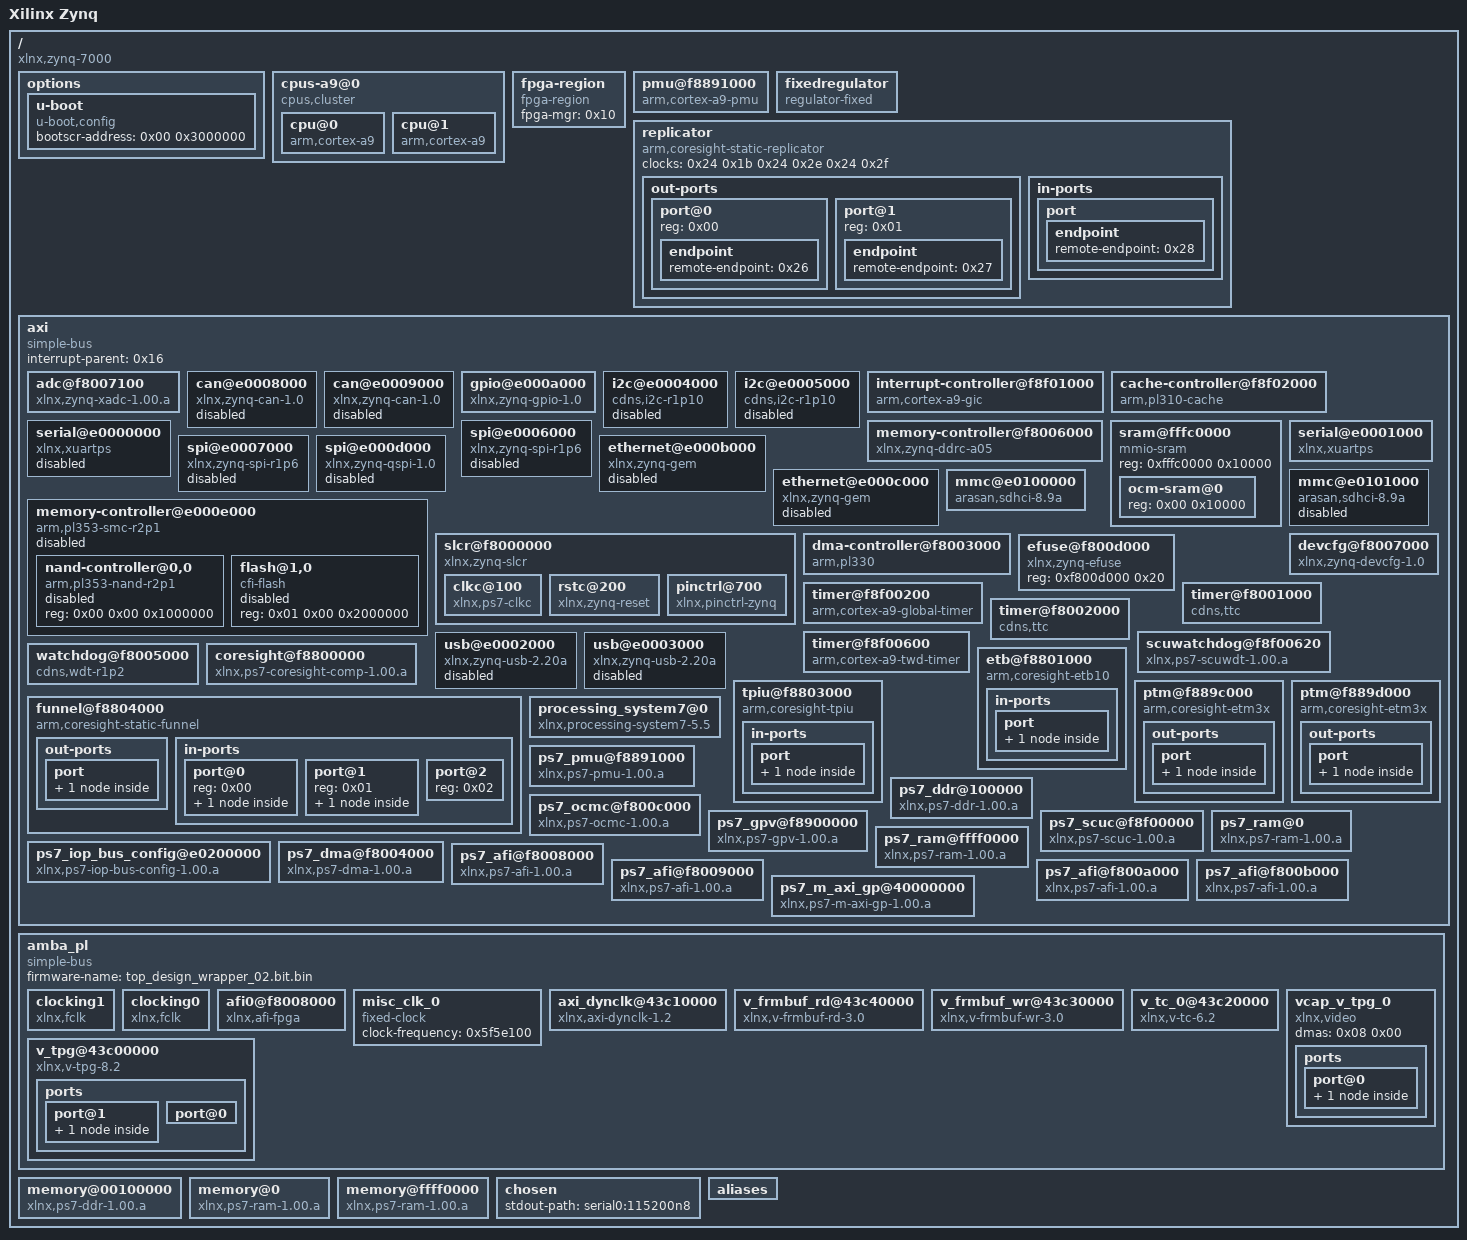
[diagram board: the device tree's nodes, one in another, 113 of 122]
/dts-v1/;

/ {
	#address-cells = <0x01>;
	#size-cells = <0x01>;
	compatible = "xlnx,zynq-7000";
	model = "Xilinx Zynq";
	device_id = "7z020";
	slrcount = <0x01>;
	family = "Zynq";
	speed_grade = "2";

	options {

		u-boot {
			compatible = "u-boot,config";
			bootscr-address = <0x00 0x3000000>;
		};
	};

	cpus-a9@0 {
		#address-cells = <0x01>;
		#size-cells = <0x00>;
		compatible = "cpus,cluster";
		address-map = <0xf0000000 0x01 0xf0000000 0x10000000 0x100000 0x02 0x100000 0x1ff00000 0x00 0x03 0x00 0x30000 0xffff0000 0x04 0xffff0000 0xfe00 0x43c00000 0x05 0x43c00000 0x10000 0x43c10000 0x06 0x43c10000 0x10000 0x43c20000 0x07 0x43c20000 0x10000 0x43c30000 0x08 0x43c30000 0x10000 0x43c40000 0x09 0x43c40000 0x10000 0xf8008000 0x0a 0xf8008000 0x1000 0xf8009000 0x0b 0xf8009000 0x1000 0xf800a000 0x0c 0xf800a000 0x1000 0xf800b000 0x0d 0xf800b000 0x1000 0xf8800000 0x0e 0xf8800000 0x100000 0xf8006000 0x0f 0xf8006000 0x1000 0xf8007000 0x10 0xf8007000 0x100 0xf8004000 0x11 0xf8004000 0x1000 0xf8003000 0x12 0xf8003000 0x1000 0xf8f00200 0x13 0xf8f00200 0x100 0xe000a000 0x14 0xe000a000 0x1000 0xf8900000 0x15 0xf8900000 0x100000 0xf8f01000 0x16 0xf8f01000 0x1000 0xe0200000 0x17 0xe0200000 0x1000 0xf8f02000 0x18 0xf8f02000 0x1000 0xf800c000 0x19 0xf800c000 0x1000 0xf8891000 0x1a 0xf8891000 0x1000 0xf8f00000 0x1b 0xf8f00000 0xfd 0xf8f00600 0x1c 0xf8f00600 0x20 0xf8f00620 0x1d 0xf8f00620 0xe0 0xe0100000 0x1e 0xe0100000 0x1000 0xf8000000 0x1f 0xf8000000 0x1000 0xf8001000 0x20 0xf8001000 0x1000 0xf8002000 0x21 0xf8002000 0x1000 0xe0001000 0x22 0xe0001000 0x1000 0xf8007100 0x23 0xf8007100 0x21>;
		#ranges-address-cells = <0x01>;
		#ranges-size-cells = <0x01>;
		phandle = <0x35>;

		cpu@0 {
			compatible = "arm,cortex-a9";
			device_type = "cpu";
			reg = <0x00>;
			clocks = <0x24 0x03>;
			clock-latency = <0x3e8>;
			cpu0-supply = <0x25>;
			operating-points = <0xa2c2b 0xf4240 0x51616 0xf4240>;
			xlnx,i-cache-size = <0x8000>;
			xlnx,d-cache-line-size = <0x14>;
			xlnx,i-cache-line-size = <0x14>;
			xlnx,cpu-1x-clk-freq-hz = <0x69f6bcb>;
			xlnx,ip-name = "ps7_cortexa9";
			xlnx,d-cache-size = <0x8000>;
			xlnx,num-cores = <0x02>;
			xlnx,cpu-clk-freq-hz = <0x27bc86bf>;
			bus-handle = <0x01>;
			phandle = <0x2e>;
		};

		cpu@1 {
			compatible = "arm,cortex-a9";
			device_type = "cpu";
			reg = <0x01>;
			clocks = <0x24 0x03>;
			xlnx,i-cache-size = <0x8000>;
			xlnx,d-cache-line-size = <0x14>;
			xlnx,i-cache-line-size = <0x14>;
			xlnx,cpu-1x-clk-freq-hz = <0x69f6bcb>;
			xlnx,ip-name = "ps7_cortexa9";
			xlnx,d-cache-size = <0x8000>;
			xlnx,cpu-clk-freq-hz = <0x27bc86bf>;
			bus-handle = <0x01>;
			phandle = <0x30>;
		};
	};

	fpga-region {
		compatible = "fpga-region";
		fpga-mgr = <0x10>;
		#address-cells = <0x01>;
		#size-cells = <0x01>;
		ranges;
		phandle = <0x36>;
	};

	pmu@f8891000 {
		compatible = "arm,cortex-a9-pmu";
		interrupts = <0x00 0x05 0x04 0x00 0x06 0x04>;
		interrupt-parent = <0x16>;
		reg = <0xf8891000 0x1000 0xf8893000 0x1000>;
	};

	fixedregulator {
		compatible = "regulator-fixed";
		regulator-name = "VCCPINT";
		regulator-min-microvolt = <0xf4240>;
		regulator-max-microvolt = <0xf4240>;
		regulator-boot-on;
		regulator-always-on;
		phandle = <0x25>;
	};

	replicator {
		compatible = "arm,coresight-static-replicator";
		clocks = <0x24 0x1b 0x24 0x2e 0x24 0x2f>;
		clock-names = "apb_pclk\0dbg_trc\0dbg_apb";

		out-ports {
			#address-cells = <0x01>;
			#size-cells = <0x00>;

			port@0 {
				reg = <0x00>;

				endpoint {
					remote-endpoint = <0x26>;
					phandle = <0x2a>;
				};
			};

			port@1 {
				reg = <0x01>;

				endpoint {
					remote-endpoint = <0x27>;
					phandle = <0x29>;
				};
			};
		};

		in-ports {

			port {

				endpoint {
					remote-endpoint = <0x28>;
					phandle = <0x2b>;
				};
			};
		};
	};

	axi {
		bootph-all;
		compatible = "simple-bus";
		#address-cells = <0x01>;
		#size-cells = <0x01>;
		interrupt-parent = <0x16>;
		ranges;
		phandle = <0x01>;

		adc@f8007100 {
			compatible = "xlnx,zynq-xadc-1.00.a";
			reg = <0xf8007100 0x20>;
			interrupts = <0x00 0x07 0x04>;
			interrupt-parent = <0x16>;
			clocks = <0x24 0x0c>;
			status = "okay";
			xlnx,ip-name = "ps7_xadc";
			xlnx,name = "ps7_xadc_0";
			phandle = <0x23>;
		};

		can@e0008000 {
			compatible = "xlnx,zynq-can-1.0";
			status = "disabled";
			clocks = <0x24 0x13 0x24 0x24>;
			clock-names = "can_clk\0pclk";
			reg = <0xe0008000 0x1000>;
			interrupts = <0x00 0x1c 0x04>;
			interrupt-parent = <0x16>;
			tx-fifo-depth = <0x40>;
			rx-fifo-depth = <0x40>;
			phandle = <0x37>;
		};

		can@e0009000 {
			compatible = "xlnx,zynq-can-1.0";
			status = "disabled";
			clocks = <0x24 0x14 0x24 0x25>;
			clock-names = "can_clk\0pclk";
			reg = <0xe0009000 0x1000>;
			interrupts = <0x00 0x33 0x04>;
			interrupt-parent = <0x16>;
			tx-fifo-depth = <0x40>;
			rx-fifo-depth = <0x40>;
			phandle = <0x38>;
		};

		gpio@e000a000 {
			compatible = "xlnx,zynq-gpio-1.0";
			#gpio-cells = <0x02>;
			clocks = <0x24 0x2a>;
			gpio-controller;
			interrupt-controller;
			#interrupt-cells = <0x02>;
			interrupt-parent = <0x16>;
			interrupts = <0x00 0x14 0x04>;
			reg = <0xe000a000 0x1000>;
			xlnx,mio-gpio-mask = <0x5600>;
			status = "okay";
			gpio-mask-high = <0x00>;
			xlnx,emio-gpio-width = <0x20>;
			xlnx,ip-name = "ps7_gpio";
			gpio-mask-low = <0x5600>;
			emio-gpio-width = <0x20>;
			xlnx,name = "ps7_gpio_0";
			phandle = <0x14>;
		};

		i2c@e0004000 {
			compatible = "cdns,i2c-r1p10";
			status = "disabled";
			clocks = <0x24 0x26>;
			interrupt-parent = <0x16>;
			interrupts = <0x00 0x19 0x04>;
			clock-frequency = <0x61a80>;
			reg = <0xe0004000 0x1000>;
			#address-cells = <0x01>;
			#size-cells = <0x00>;
			phandle = <0x39>;
		};

		i2c@e0005000 {
			compatible = "cdns,i2c-r1p10";
			status = "disabled";
			clocks = <0x24 0x27>;
			interrupt-parent = <0x16>;
			interrupts = <0x00 0x30 0x04>;
			clock-frequency = <0x61a80>;
			reg = <0xe0005000 0x1000>;
			#address-cells = <0x01>;
			#size-cells = <0x00>;
			phandle = <0x3a>;
		};

		interrupt-controller@f8f01000 {
			compatible = "arm,cortex-a9-gic";
			#interrupt-cells = <0x03>;
			interrupt-controller;
			reg = <0xf8f01000 0x1000 0xf8f00100 0x100>;
			status = "okay";
			xlnx,irq-f2p-mode = "DIRECT";
			xlnx,ip-name = "ps7_intc_dist";
			xlnx,name = "ps7_intc_dist_0";
			phandle = <0x16>;
		};

		cache-controller@f8f02000 {
			compatible = "arm,pl310-cache";
			reg = <0xf8f02000 0x1000>;
			interrupts = <0x00 0x02 0x04>;
			arm,data-latency = <0x03 0x02 0x02>;
			arm,tag-latency = <0x02 0x02 0x02>;
			cache-unified;
			cache-level = <0x02>;
			status = "okay";
			xlnx,ip-name = "ps7_pl310";
			xlnx,name = "ps7_pl310_0";
			phandle = <0x18>;
		};

		memory-controller@f8006000 {
			compatible = "xlnx,zynq-ddrc-a05";
			reg = <0xf8006000 0x1000>;
			status = "okay";
			xlnx,ddr-clk-freq-hz = <0x1fca057e>;
			xlnx,ip-name = "ps7_ddrc";
			xlnx,has-ecc = <0x00>;
			xlnx,name = "ps7_ddrc_0";
			phandle = <0x0f>;
		};

		sram@fffc0000 {
			compatible = "mmio-sram";
			reg = <0xfffc0000 0x10000>;
			#address-cells = <0x01>;
			#size-cells = <0x01>;
			ranges = <0x00 0xfffc0000 0x10000>;
			phandle = <0x3b>;

			ocm-sram@0 {
				reg = <0x00 0x10000>;
			};
		};

		serial@e0000000 {
			compatible = "xlnx,xuartps\0cdns,uart-r1p8";
			status = "disabled";
			clocks = <0x24 0x17 0x24 0x28>;
			clock-names = "uart_clk\0pclk";
			reg = <0xe0000000 0x1000>;
			interrupts = <0x00 0x1b 0x04>;
			interrupt-parent = <0x16>;
			phandle = <0x3c>;
		};

		serial@e0001000 {
			compatible = "xlnx,xuartps\0cdns,uart-r1p8";
			status = "okay";
			clocks = <0x24 0x18 0x24 0x29>;
			clock-names = "uart_clk\0pclk";
			reg = <0xe0001000 0x1000>;
			interrupts = <0x00 0x32 0x04>;
			interrupt-parent = <0x16>;
			xlnx,clock-freq = <0x5f5e100>;
			xlnx,has-modem = <0x00>;
			xlnx,ip-name = "ps7_uart";
			cts-override;
			port-number = <0x00>;
			xlnx,uart-clk-freq-hz = <0x5f5e100>;
			xlnx,name = "ps7_uart_1";
			phandle = <0x22>;
		};

		spi@e0006000 {
			compatible = "xlnx,zynq-spi-r1p6";
			reg = <0xe0006000 0x1000>;
			status = "disabled";
			interrupt-parent = <0x16>;
			interrupts = <0x00 0x1a 0x04>;
			clocks = <0x24 0x19 0x24 0x22>;
			clock-names = "ref_clk\0pclk";
			#address-cells = <0x01>;
			#size-cells = <0x00>;
			phandle = <0x3d>;
		};

		spi@e0007000 {
			compatible = "xlnx,zynq-spi-r1p6";
			reg = <0xe0007000 0x1000>;
			status = "disabled";
			interrupt-parent = <0x16>;
			interrupts = <0x00 0x31 0x04>;
			clocks = <0x24 0x1a 0x24 0x23>;
			clock-names = "ref_clk\0pclk";
			#address-cells = <0x01>;
			#size-cells = <0x00>;
			phandle = <0x3e>;
		};

		spi@e000d000 {
			compatible = "xlnx,zynq-qspi-1.0";
			reg = <0xe000d000 0x1000>;
			interrupt-parent = <0x16>;
			interrupts = <0x00 0x13 0x04>;
			clocks = <0x24 0x0a 0x24 0x2b>;
			clock-names = "ref_clk\0pclk";
			status = "disabled";
			#address-cells = <0x01>;
			#size-cells = <0x00>;
			phandle = <0x3f>;
		};

		ethernet@e000b000 {
			compatible = "xlnx,zynq-gem\0cdns,gem";
			reg = <0xe000b000 0x1000>;
			status = "disabled";
			interrupts = <0x00 0x16 0x04>;
			interrupt-parent = <0x16>;
			clocks = <0x24 0x1e 0x24 0x1e 0x24 0x0d>;
			clock-names = "pclk\0hclk\0tx_clk";
			#address-cells = <0x01>;
			#size-cells = <0x00>;
			phandle = <0x40>;
		};

		ethernet@e000c000 {
			compatible = "xlnx,zynq-gem\0cdns,gem";
			reg = <0xe000c000 0x1000>;
			status = "disabled";
			interrupts = <0x00 0x2d 0x04>;
			interrupt-parent = <0x16>;
			clocks = <0x24 0x1f 0x24 0x1f 0x24 0x0e>;
			clock-names = "pclk\0hclk\0tx_clk";
			#address-cells = <0x01>;
			#size-cells = <0x00>;
			phandle = <0x41>;
		};

		memory-controller@e000e000 {
			compatible = "arm,pl353-smc-r2p1\0arm,primecell";
			reg = <0xe000e000 0x1000>;
			status = "disabled";
			clock-names = "memclk\0apb_pclk";
			clocks = <0x24 0x0b 0x24 0x2c>;
			ranges = <0x00 0x00 0xe1000000 0x1000000 0x01 0x00 0xe2000000 0x2000000 0x02 0x00 0xe4000000 0x2000000>;
			#address-cells = <0x02>;
			#size-cells = <0x01>;
			interrupt-parent = <0x16>;
			interrupts = <0x00 0x12 0x04>;
			phandle = <0x42>;

			nand-controller@0,0 {
				compatible = "arm,pl353-nand-r2p1";
				reg = <0x00 0x00 0x1000000>;
				status = "disabled";
				phandle = <0x43>;
			};

			flash@1,0 {
				status = "disabled";
				compatible = "cfi-flash";
				reg = <0x01 0x00 0x2000000>;
				phandle = <0x44>;
			};
		};

		mmc@e0100000 {
			compatible = "arasan,sdhci-8.9a";
			status = "okay";
			clock-names = "clk_xin\0clk_ahb";
			clocks = <0x24 0x15 0x24 0x20>;
			interrupt-parent = <0x16>;
			interrupts = <0x00 0x18 0x04>;
			reg = <0xe0100000 0x1000>;
			xlnx,has-power = <0x00>;
			xlnx,ip-name = "ps7_sdio";
			xlnx,sdio-clk-freq-hz = <0x5f5e100>;
			xlnx,has-wp = <0x00>;
			xlnx,has-cd = <0x00>;
			xlnx,name = "ps7_sd_0";
			phandle = <0x1e>;
		};

		mmc@e0101000 {
			compatible = "arasan,sdhci-8.9a";
			status = "disabled";
			clock-names = "clk_xin\0clk_ahb";
			clocks = <0x24 0x16 0x24 0x21>;
			interrupt-parent = <0x16>;
			interrupts = <0x00 0x2f 0x04>;
			reg = <0xe0101000 0x1000>;
			phandle = <0x45>;
		};

		slcr@f8000000 {
			bootph-all;
			#address-cells = <0x01>;
			#size-cells = <0x01>;
			compatible = "xlnx,zynq-slcr\0syscon\0simple-mfd";
			reg = <0xf8000000 0x1000>;
			ranges;
			status = "okay";
			xlnx,ip-name = "ps7_slcr";
			xlnx,name = "ps7_slcr_0";
			phandle = <0x1f>;

			clkc@100 {
				bootph-all;
				#clock-cells = <0x01>;
				compatible = "xlnx,ps7-clkc";
				fclk-enable = <0x03>;
				clock-output-names = "armpll\0ddrpll\0iopll\0cpu_6or4x\0cpu_3or2x\0cpu_2x\0cpu_1x\0ddr2x\0ddr3x\0dci\0lqspi\0smc\0pcap\0gem0\0gem1\0fclk0\0fclk1\0fclk2\0fclk3\0can0\0can1\0sdio0\0sdio1\0uart0\0uart1\0spi0\0spi1\0dma\0usb0_aper\0usb1_aper\0gem0_aper\0gem1_aper\0sdio0_aper\0sdio1_aper\0spi0_aper\0spi1_aper\0can0_aper\0can1_aper\0i2c0_aper\0i2c1_aper\0uart0_aper\0uart1_aper\0gpio_aper\0lqspi_aper\0smc_aper\0swdt\0dbg_trc\0dbg_apb";
				reg = <0x100 0x100>;
				ps-clk-frequency = <0x1fca055>;
				phandle = <0x24>;
			};

			rstc@200 {
				compatible = "xlnx,zynq-reset";
				reg = <0x200 0x48>;
				#reset-cells = <0x01>;
				syscon = <0x1f>;
				phandle = <0x46>;
			};

			pinctrl@700 {
				compatible = "xlnx,pinctrl-zynq";
				reg = <0x700 0x200>;
				syscon = <0x1f>;
				phandle = <0x47>;
			};
		};

		dma-controller@f8003000 {
			compatible = "arm,pl330\0arm,primecell";
			reg = <0xf8003000 0x1000>;
			interrupt-parent = <0x16>;
			interrupts = <0x00 0x0d 0x04 0x00 0x0e 0x04 0x00 0x0f 0x04 0x00 0x10 0x04 0x00 0x11 0x04 0x00 0x28 0x04 0x00 0x29 0x04 0x00 0x2a 0x04 0x00 0x2b 0x04>;
			#dma-cells = <0x01>;
			clocks = <0x24 0x1b>;
			clock-names = "apb_pclk";
			status = "okay";
			xlnx,ip-name = "ps7_dma";
			xlnx,is-secure;
			xlnx,name = "ps7_dma_s";
			phandle = <0x12>;
		};

		devcfg@f8007000 {
			compatible = "xlnx,zynq-devcfg-1.0";
			reg = <0xf8007000 0x100>;
			interrupt-parent = <0x16>;
			interrupts = <0x00 0x08 0x04>;
			clocks = <0x24 0x0c 0x24 0x0f 0x24 0x10 0x24 0x11 0x24 0x12>;
			clock-names = "ref_clk\0fclk0\0fclk1\0fclk2\0fclk3";
			syscon = <0x1f>;
			status = "okay";
			xlnx,ip-name = "ps7_dev_cfg";
			xlnx,name = "ps7_dev_cfg_0";
			phandle = <0x10>;
		};

		efuse@f800d000 {
			compatible = "xlnx,zynq-efuse";
			reg = <0xf800d000 0x20>;
			phandle = <0x48>;
		};

		timer@f8f00200 {
			compatible = "arm,cortex-a9-global-timer";
			reg = <0xf8f00200 0x20>;
			interrupts = <0x01 0x0b 0x301>;
			interrupt-parent = <0x16>;
			clocks = <0x24 0x04>;
			status = "okay";
			xlnx,ip-name = "ps7_globaltimer";
			xlnx,name = "ps7_globaltimer_0";
			phandle = <0x13>;
		};

		timer@f8001000 {
			interrupt-parent = <0x16>;
			interrupts = <0x00 0x0a 0x04 0x00 0x0b 0x04 0x00 0x0c 0x04>;
			compatible = "cdns,ttc";
			clocks = <0x24 0x06>;
			reg = <0xf8001000 0x1000>;
			xlnx,ttc-clk2-freq-hz = <0x69f6bcb>;
			xlnx,ttc-clk1-clksrc = <0x00>;
			status = "okay";
			xlnx,clock-freq = <0x69f6bcb>;
			xlnx,ttc-clk2-clksrc = <0x00>;
			xlnx,ip-name = "ps7_ttc";
			xlnx,ttc-clk0-freq-hz = <0x69f6bcb>;
			xlnx,ttc-clk1-freq-hz = <0x69f6bcb>;
			xlnx,ttc-clk0-clksrc = <0x00>;
			xlnx,name = "ps7_ttc_0";
			phandle = <0x20>;
		};

		timer@f8002000 {
			interrupt-parent = <0x16>;
			interrupts = <0x00 0x25 0x04 0x00 0x26 0x04 0x00 0x27 0x04>;
			compatible = "cdns,ttc";
			clocks = <0x24 0x06>;
			reg = <0xf8002000 0x1000>;
			xlnx,ttc-clk2-freq-hz = <0x69f6bcb>;
			xlnx,ttc-clk1-clksrc = <0x00>;
			status = "okay";
			xlnx,clock-freq = <0x69f6bcb>;
			xlnx,ttc-clk2-clksrc = <0x00>;
			xlnx,ip-name = "ps7_ttc";
			xlnx,ttc-clk0-freq-hz = <0x69f6bcb>;
			xlnx,ttc-clk1-freq-hz = <0x69f6bcb>;
			xlnx,ttc-clk0-clksrc = <0x00>;
			xlnx,name = "ps7_ttc_1";
			phandle = <0x21>;
		};

		timer@f8f00600 {
			bootph-all;
			interrupt-parent = <0x16>;
			interrupts = <0x01 0x0d 0x301>;
			compatible = "arm,cortex-a9-twd-timer";
			reg = <0xf8f00600 0x20>;
			clocks = <0x24 0x04>;
			status = "okay";
			xlnx,ip-name = "ps7_scutimer";
			xlnx,name = "ps7_scutimer_0";
			phandle = <0x1c>;
		};

		scuwatchdog@f8f00620 {
			interrupt-parent = <0x16>;
			interrupts = <0x01 0x0e 0x04>;
			compatible = "xlnx,ps7-scuwdt-1.00.a";
			reg = <0xf8f00620 0xe0>;
			status = "okay";
			xlnx,ip-name = "ps7_scuwdt";
			xlnx,name = "ps7_scuwdt_0";
			phandle = <0x1d>;
		};

		usb@e0002000 {
			compatible = "xlnx,zynq-usb-2.20a\0chipidea,usb2";
			status = "disabled";
			clocks = <0x24 0x1c>;
			interrupt-parent = <0x16>;
			interrupts = <0x00 0x15 0x04>;
			reg = <0xe0002000 0x1000>;
			phy_type = "ulpi";
			phandle = <0x49>;
		};

		usb@e0003000 {
			compatible = "xlnx,zynq-usb-2.20a\0chipidea,usb2";
			status = "disabled";
			clocks = <0x24 0x1d>;
			interrupt-parent = <0x16>;
			interrupts = <0x00 0x2c 0x04>;
			reg = <0xe0003000 0x1000>;
			phy_type = "ulpi";
			phandle = <0x4a>;
		};

		watchdog@f8005000 {
			clocks = <0x24 0x2d>;
			compatible = "cdns,wdt-r1p2";
			interrupt-parent = <0x16>;
			interrupts = <0x00 0x09 0x01>;
			reg = <0xf8005000 0x1000>;
			timeout-sec = <0x0a>;
			phandle = <0x4b>;
		};

		coresight@f8800000 {
			compatible = "xlnx,ps7-coresight-comp-1.00.a";
			status = "okay";
			reg = <0xf8800000 0x100000>;
			xlnx,ip-name = "ps7_coresight_comp";
			xlnx,name = "ps7_coresight_comp_0";
			phandle = <0x0e>;
		};

		etb@f8801000 {
			compatible = "arm,coresight-etb10\0arm,primecell";
			reg = <0xf8801000 0x1000>;
			clocks = <0x24 0x1b 0x24 0x2e 0x24 0x2f>;
			clock-names = "apb_pclk\0dbg_trc\0dbg_apb";

			in-ports {

				port {

					endpoint {
						remote-endpoint = <0x29>;
						phandle = <0x27>;
					};
				};
			};
		};

		tpiu@f8803000 {
			compatible = "arm,coresight-tpiu\0arm,primecell";
			reg = <0xf8803000 0x1000>;
			clocks = <0x24 0x1b 0x24 0x2e 0x24 0x2f>;
			clock-names = "apb_pclk\0dbg_trc\0dbg_apb";

			in-ports {

				port {

					endpoint {
						remote-endpoint = <0x2a>;
						phandle = <0x26>;
					};
				};
			};
		};

		funnel@f8804000 {
			compatible = "arm,coresight-static-funnel\0arm,primecell";
			reg = <0xf8804000 0x1000>;
			clocks = <0x24 0x1b 0x24 0x2e 0x24 0x2f>;
			clock-names = "apb_pclk\0dbg_trc\0dbg_apb";

			out-ports {

				port {

					endpoint {
						remote-endpoint = <0x2b>;
						phandle = <0x28>;
					};
				};
			};

			in-ports {
				#address-cells = <0x01>;
				#size-cells = <0x00>;

				port@0 {
					reg = <0x00>;

					endpoint {
						remote-endpoint = <0x2c>;
						phandle = <0x2f>;
					};
				};

				port@1 {
					reg = <0x01>;

					endpoint {
						remote-endpoint = <0x2d>;
						phandle = <0x31>;
					};
				};

				port@2 {
					reg = <0x02>;
				};
			};
		};

		ptm@f889c000 {
			compatible = "arm,coresight-etm3x\0arm,primecell";
			reg = <0xf889c000 0x1000>;
			clocks = <0x24 0x1b 0x24 0x2e 0x24 0x2f>;
			clock-names = "apb_pclk\0dbg_trc\0dbg_apb";
			cpu = <0x2e>;

			out-ports {

				port {

					endpoint {
						remote-endpoint = <0x2f>;
						phandle = <0x2c>;
					};
				};
			};
		};

		ptm@f889d000 {
			compatible = "arm,coresight-etm3x\0arm,primecell";
			reg = <0xf889d000 0x1000>;
			clocks = <0x24 0x1b 0x24 0x2e 0x24 0x2f>;
			clock-names = "apb_pclk\0dbg_trc\0dbg_apb";
			cpu = <0x30>;

			out-ports {

				port {

					endpoint {
						remote-endpoint = <0x31>;
						phandle = <0x2d>;
					};
				};
			};
		};

		processing_system7@0 {
			xlnx,pcw-act-enet0-peripheral-freqmhz = <0x0a>;
			xlnx,pcw-nor-grp-sram-cs1-io = "<Select>";
			xlnx,num-f2p-intr-inputs = <0x04>;
			reg = <0x00 0x20000000>;
			xlnx,pcw-mio-18-direction = "<Select>";
			xlnx,pcw-nand-cycles-t-ar = <0x01>;
			xlnx,pcw-p2f-dmac7-intr = <0x00>;
			xlnx,pcw-en-clk1-port = <0x01>;
			xlnx,pcw-crystal-peripheral-freqmhz = <0x1fca055>;
			xlnx,pcw-nor-grp-sram-cs1-enable = <0x00>;
			xlnx,pcw-uiparam-ddr-dq-1-package-length = <0x416881c>;
			xlnx,pcw-act-wdt-peripheral-freqmhz = <0x69f6bcb>;
			xlnx,pcw-p2f-dmac4-intr = <0x00>;
			xlnx,pcw-s-axi-hp3-id-width = <0x06>;
			xlnx,pcw-en-emio-uart0 = <0x00>;
			xlnx,pcw-en-emio-uart1 = <0x00>;
			xlnx,pcw-ddr-hpr-to-critical-priority-level = <0x0f>;
			xlnx,pcw-enet-reset-polarity = "Active , Low";
			xlnx,pcw-mio-5-direction = "<Select>";
			xlnx,pcw-p2f-dmac1-intr = <0x00>;
			xlnx,pcw-sd0-grp-cd-enable = <0x00>;
			xlnx,pcw-act-fpga1-peripheral-freqmhz = <0x8d48fc3>;
			xlnx,pcw-mio-24-iotype = "<Select>";
			xlnx,pcw-ddr-port1-hpr-enable = <0x00>;
			xlnx,pcw-cpu-peripheral-clksrc = "ARM , PLL";
			xlnx,pcw-mio-53-pullup = "<Select>";
			xlnx,pcw-use-axi-nonsecure = <0x00>;
			xlnx,pcw-spi1-grp-ss0-io = "<Select>";
			xlnx,pcw-uiparam-ddr-dqs-1-propogation-delay = <0xa0>;
			xlnx,pcw-nor-cs1-t-pc = <0x01>;
			xlnx,pcw-s-axi-gp0-id-width = <0x06>;
			xlnx,pcw-trace-grp-8bit-io = "<Select>";
			xlnx,pcw-ttc-peripheral-freqmhz = <0x32>;
			xlnx,pcw-ftm-cti-out0 = "<Select>";
			xlnx,pcw-ttc1-clk0-peripheral-divisor0 = <0x01>;
			xlnx,pcw-uiparam-ddr-clock-stop-en = <0x00>;
			xlnx,pcw-ftm-cti-out1 = "<Select>";
			xlnx,pcw-mio-28-direction = "<Select>";
			xlnx,pcw-en-ttc0 = <0x01>;
			xlnx,pcw-ftm-cti-out2 = "<Select>";
			xlnx,pcw-mio-11-pullup = "<Select>";
			xlnx,pcw-en-ttc1 = <0x01>;
			xlnx,pcw-ftm-cti-out3 = "<Select>";
			xlnx,pcw-m-axi-gp0-thread-id-width = <0x0c>;
			xlnx,pcw-nor-sram-cs1-t-ceoe = <0x01>;
			xlnx,pcw-nor-grp-sram-int-enable = <0x00>;
			xlnx,pcw-can-peripheral-clksrc = "IO , PLL";
			xlnx,pcw-ttc1-clk0-peripheral-clksrc = "CPU_1X";
			xlnx,mio-primitive = <0x36>;
			xlnx,pcw-gp0-num-write-threads = <0x04>;
			xlnx,pcw-mio-4-iotype = "<Select>";
			xlnx,pcw-mio-41-iotype = "LVCMOS , 1.8V";
			xlnx,pcw-nor-cs1-t-rc = <0x0b>;
			xlnx,pcw-i2c0-grp-int-enable = <0x00>;
			xlnx,pcw-ddr-port2-hpr-enable = <0x00>;
			xlnx,pcw-act-tpiu-peripheral-freqmhz = <0xc8>;
			xlnx,pcw-package-name = "clg400";
			xlnx,pcw-s-axi-hp0-id-width = <0x06>;
			xlnx,pcw-package-ddr-dqs-to-clk-delay-0 = <0xffffffff 0xffff9e58>;
			xlnx,pcw-uiparam-ddr-dqs-3-length-mm = <0x00>;
			xlnx,pcw-package-ddr-dqs-to-clk-delay-1 = <0x36b0>;
			xlnx,pcw-qspi-grp-single-ss-enable = <0x00>;
			xlnx,pcw-act-usb0-peripheral-freqmhz = <0x3c>;
			xlnx,pcw-mio-27-pullup = "<Select>";
			xlnx,pcw-package-ddr-dqs-to-clk-delay-2 = <0xffffffff 0xffffdcd8>;
			xlnx,pcw-mio-38-direction = "<Select>";
			xlnx,pcw-package-ddr-dqs-to-clk-delay-3 = <0xffffffff 0xffff7f18>;
			xlnx,pcw-en-spi0 = <0x00>;
			xlnx,pcw-en-spi1 = <0x00>;
			xlnx,pcw-include-acp-trans-check = <0x00>;
			xlnx,pcw-ttc1-clk1-peripheral-divisor0 = <0x01>;
			xlnx,en-emio-pjtag = <0x00>;
			xlnx,pcw-nor-sram-cs0-we-time = <0x00>;
			xlnx,pcw-uiparam-ddr-speed-bin = "DDR3_1066F";
			xlnx,pcw-ddr-port3-hpr-enable = <0x00>;
			xlnx,pcw-irq-f2p-intr = <0x01>;
			xlnx,pcw-trace-peripheral-enable = <0x00>;
			xlnx,pcw-enet0-grp-mdio-io = "<Select>";
			xlnx,pcw-mio-15-iotype = "<Select>";
			xlnx,pcw-nor-cs1-t-tr = <0x01>;
			xlnx,pcw-mio-7-pullup = "<Select>";
			xlnx,pcw-mio-44-pullup = "enabled";
			xlnx,pcw-uiparam-act-ddr-freq-mhz = <0x1fca057e>;
			xlnx,pcw-use-ps-slcr-registers = <0x00>;
			xlnx,pcw-mio-48-direction = "out";
			xlnx,pcw-ttc0-clk0-peripheral-divisor0 = <0x01>;
			xlnx,pcw-trace-grp-4bit-io = "<Select>";
			xlnx,pcw-nor-cs1-t-wc = <0x0b>;
			xlnx,pcw-gpio-peripheral-enable = <0x00>;
			xlnx,pcw-nor-cs0-t-ceoe = <0x01>;
			xlnx,pcw-spi-peripheral-clksrc = "IO , PLL";
			xlnx,pcw-p2f-i2c0-intr = <0x00>;
			xlnx,pcw-uiparam-ddr-clock-2-package-length = <0x4cb9f7c>;
			status = "okay";
			xlnx,pcw-act-can-peripheral-freqmhz = <0x0a>;
			xlnx,pcw-ttc1-clk2-peripheral-divisor0 = <0x01>;
			xlnx,pcw-mio-32-iotype = "<Select>";
			xlnx,pcw-p2f-gpio-intr = <0x00>;
			xlnx,pcw-ttc0-clk1-peripheral-freqmhz = <0x7f28155>;
			xlnx,pcw-value-silversion = <0x03>;
			xlnx,pcw-nor-cs1-t-wp = <0x01>;
			xlnx,pcw-pcap-peripheral-divisor0 = <0x09>;
			xlnx,pcw-spi1-spi1-io = "<Select>";
			xlnx,pcw-wdt-peripheral-freqmhz = <0x7f28155>;
			xlnx,pcw-mio-18-pullup = "<Select>";
			xlnx,pcw-uart1-baud-rate = <0x1c200>;
			xlnx,pcw-mio-17-direction = "<Select>";
			xlnx,pcw-trace-grp-2bit-io = "<Select>";
			xlnx,pcw-ttc0-clk1-peripheral-divisor0 = <0x01>;
			xlnx,pcw-spi0-grp-ss2-enable = <0x00>;
			xlnx,pcw-mio-48-iotype = "LVCMOS , 1.8V";
			xlnx,pcw-gp1-num-read-threads = <0x04>;
			xlnx,pcw-i2c1-i2c1-io = "<Select>";
			xlnx,pcw-sd0-sd0-io = "MIO , 40 , .. , 45";
			xlnx,pcw-can0-grp-clk-enable = <0x00>;
			xlnx,pcw-mio-4-direction = "<Select>";
			xlnx,pcw-use-s-axi-acp = <0x00>;
			xlnx,pcw-uart-peripheral-freqmhz = <0x64>;
			xlnx,pcw-mio-35-pullup = "<Select>";
			xlnx,pcw-uiparam-ddr-partno = "MT41J256M16 , RE-125";
			xlnx,pcw-qspi-peripheral-freqmhz = <0xc8>;
			xlnx,pcw-mio-27-direction = "<Select>";
			xlnx,pcw-mio-52-slew = "<Select>";
			xlnx,pcw-can0-peripheral-clksrc = "External";
			xlnx,pcw-uiparam-ddr-dram-width = "16 , Bits";
			xlnx,pcw-nand-cycles-t-rc = <0x0b>;
			xlnx,pcw-nand-nand-io = "<Select>";
			xlnx,pcw-nor-grp-sram-cs0-enable = <0x00>;
			xlnx,pcw-clk1-freq = <0x8d48fc3>;
			xlnx,pcw-mio-48-slew = "slow";
			xlnx,pcw-m-axi-gp0-freqmhz = <0x64>;
			xlnx,pcw-ttc0-clk2-peripheral-divisor0 = <0x01>;
			xlnx,pcw-mio-45-slew = "slow";
			xlnx,pcw-mio-23-iotype = "<Select>";
			xlnx,pcw-mio-42-slew = "slow";
			xlnx,pcw-mio-52-pullup = "<Select>";
			xlnx,m-axi-gp1-id-width = <0x0c>;
			xlnx,pcw-fclk-clk1-buf;
			xlnx,pcw-dual-parallel-qspi-data-mode = "<Select>";
			xlnx,pcw-nand-cycles-t-rr = <0x01>;
			xlnx,pcw-en-rst1-port = <0x00>;
			xlnx,pcw-mio-38-slew = "<Select>";
			xlnx,pcw-uiparam-ddr-dqs-2-length-mm = <0x00>;
			xlnx,pcw-mio-10-pullup = "<Select>";
			xlnx,pcw-mio-35-slew = "<Select>";
			xlnx,pcw-mio-37-direction = "<Select>";
			xlnx,pcw-nor-sram-cs0-t-ceoe = <0x01>;
			xlnx,pcw-usb0-usb0-io = "<Select>";
			xlnx,pcw-mio-32-slew = "<Select>";
			xlnx,pcw-usb1-reset-io = "<Select>";
			xlnx,pcw-enet1-peripheral-freqmhz = "1000 , Mbps";
			xlnx,pcw-uiparam-ddr-clock-2-propogation-delay = <0xa0>;
			xlnx,pcw-qspi-grp-single-ss-io = "<Select>";
			xlnx,pcw-mio-28-slew = "<Select>";
			xlnx,pcw-mio-3-iotype = "<Select>";
			xlnx,pcw-mio-39-iotype = "<Select>";
			xlnx,pcw-mio-40-iotype = "LVCMOS , 1.8V";
			xlnx,pcw-nor-cs1-we-time = <0x00>;
			xlnx,pcw-enet1-reset-enable = <0x00>;
			xlnx,pcw-mio-25-slew = "<Select>";
			xlnx,pcw-can0-grp-clk-io = "<Select>";
			xlnx,pcw-uiparam-ddr-dq-3-length-mm = <0x00>;
			xlnx,pcw-mio-22-slew = "<Select>";
			xlnx,pcw-mio-26-pullup = "<Select>";
			xlnx,pcw-nand-cycles-t-wc = <0x0b>;
			xlnx,pcw-fpga2-peripheral-freqmhz = <0x32>;
			xlnx,pcw-mio-18-slew = "<Select>";
			xlnx,pcw-mio-47-direction = "in";
			xlnx,pcw-nor-sram-cs0-t-pc = <0x01>;
			xlnx,pcw-can-peripheral-freqmhz = <0x64>;
			xlnx,pcw-uiparam-ddr-dq-2-package-length = <0x561cad8>;
			xlnx,pcw-mio-15-slew = "<Select>";
			xlnx,emio-gpio-width = <0x20>;
			xlnx,fclk-clk2-buf;
			xlnx,s-axi-hp0-data-width = <0x20>;
			xlnx,pcw-mio-12-slew = "<Select>";
			xlnx,pcw-en-emio-wdt = <0x00>;
			xlnx,pcw-nand-cycles-t-wp = <0x01>;
			xlnx,pcw-ttc1-clk0-peripheral-freqmhz = <0x7f28155>;
			xlnx,pcw-ddr-ddr-pll-freqmhz = <0x3f940bf7>;
			xlnx,pcw-enet0-reset-enable = <0x00>;
			xlnx,pcw-preset-bank1-voltage = "LVCMOS , 1.8V";
			xlnx,pcw-can1-grp-clk-io = "<Select>";
			xlnx,pcw-nor-sram-cs0-t-rc = <0x0b>;
			xlnx,pcw-mio-14-iotype = "<Select>";
			xlnx,pcw-mio-6-pullup = "<Select>";
			xlnx,pcw-enet-reset-enable = <0x00>;
			xlnx,pcw-mio-43-pullup = "enabled";
			xlnx,pcw-spi0-peripheral-enable = <0x00>;
			xlnx,pcw-act-ttc0-clk0-peripheral-freqmhz = <0x69f6bcb>;
			xlnx,pcw-nor-grp-a25-enable = <0x00>;
			xlnx,trace-buffer-fifo-size = <0x80>;
			xlnx,pcw-uiparam-ddr-dq-1-propogation-delay = <0xa0>;
			xlnx,pcw-trace-grp-4bit-enable = <0x00>;
			xlnx,pcw-qspi-peripheral-enable = <0x00>;
			xlnx,pcw-dual-stack-qspi-data-mode = "<Select>";
			xlnx,pcw-package-ddr-board-delay0 = <0x15ba8>;
			xlnx,pcw-wdt-peripheral-divisor0 = <0x01>;
			xlnx,s-axi-hp1-data-width = <0x40>;
			xlnx,pcw-package-ddr-board-delay1 = <0x124f8>;
			xlnx,pcw-package-ddr-board-delay2 = <0x14c08>;
			xlnx,pcw-uart0-baud-rate = <0x1c200>;
			xlnx,pcw-en-wdt = <0x00>;
			xlnx,pcw-include-trace-buffer = <0x00>;
			xlnx,pcw-m-axi-gp0-id-width = <0x0c>;
			xlnx,pcw-mio-16-direction = "<Select>";
			xlnx,pcw-package-ddr-board-delay3 = <0x16760>;
			xlnx,pcw-dci-peripheral-clksrc = "DDR , PLL";
			xlnx,pcw-i2c1-grp-int-enable = <0x00>;
			xlnx,pcw-p2f-uart1-intr = <0x00>;
			xlnx,pcw-mio-31-iotype = "<Select>";
			xlnx,pcw-usb1-peripheral-enable = <0x00>;
			xlnx,pcw-act-can0-peripheral-freqmhz = <0x16b4ddc>;
			xlnx,pcw-mio-3-direction = "<Select>";
			xlnx,pcw-s-axi-hp3-freqmhz = <0x0a>;
			xlnx,pcw-m-axi-gp0-support-narrow-burst = <0x00>;
			xlnx,pcw-nor-sram-cs0-t-tr = <0x01>;
			xlnx,pcw-usb1-reset-enable = <0x00>;
			xlnx,pcw-can1-can1-io = "<Select>";
			xlnx,pcw-mio-17-pullup = "<Select>";
			xlnx,pcw-uiparam-ddr-clock-3-length-mm = <0x00>;
			xlnx,pcw-sd1-peripheral-enable = <0x00>;
			xlnx,s-axi-hp2-data-width = <0x40>;
			xlnx,pcw-en-trace = <0x00>;
			xlnx,pcw-mio-26-direction = "<Select>";
			xlnx,pcw-nor-sram-cs0-t-wc = <0x0b>;
			xlnx,pcw-spi0-grp-ss1-enable = <0x00>;
			xlnx,pcw-ttc0-clk1-peripheral-clksrc = "CPU_1X";
			xlnx,pcw-mio-47-iotype = "LVCMOS , 1.8V";
			xlnx,pcw-nand-grp-d8-io = "<Select>";
			xlnx,pcw-nor-grp-cs1-io = "<Select>";
			xlnx,pcw-en-clktrig1-port = <0x00>;
			xlnx,pcw-i2c-reset-select = "<Select>";
			xlnx,pcw-act-uart-peripheral-freqmhz = <0x64>;
			xlnx,pcw-nor-grp-cs1-enable = <0x00>;
			xlnx,pcw-usb1-peripheral-freqmhz = <0x3c>;
			xlnx,pcw-usb0-reset-enable = <0x00>;
			xlnx,m-axi-gp1-thread-id-width = <0x0c>;
			xlnx,pcw-nor-sram-cs0-t-wp = <0x01>;
			xlnx,pcw-mio-34-pullup = "<Select>";
			xlnx,pcw-act-qspi-peripheral-freqmhz = <0x0a>;
			xlnx,pcw-sdio-peripheral-valid = <0x01>;
			xlnx,pcw-en-emio-trace = <0x00>;
			xlnx,pcw-uart0-grp-full-enable = <0x00>;
			xlnx,pcw-uiparam-ddr-dqs-1-length-mm = <0x00>;
			xlnx,pcw-uiparam-ddr-clock-3-package-length = <0x4cb9f7c>;
			xlnx,s-axi-hp3-data-width = <0x40>;
			xlnx,pcw-mio-36-direction = "<Select>";
			xlnx,pcw-uiparam-generate-summary = "NONE";
			xlnx,pcw-qspi-qspi-io = "<Select>";
			xlnx,pcw-fclk0-peripheral-clksrc = "IO , PLL";
			xlnx,pcw-nand-cycles-t-clr = <0x01>;
			xlnx,pcw-pll-bypassmode-enable = <0x00>;
			xlnx,s-axi-acp-aruser-val = <0x1f>;
			xlnx,pcw-io-io-pll-freqmhz = <0x708>;
			xlnx,pcw-mio-22-iotype = "<Select>";
			xlnx,pcw-mio-51-pullup = "<Select>";
			xlnx,pcw-p2f-sdio1-intr = <0x00>;
			xlnx,pcw-qspi-grp-fbclk-io = "<Select>";
			xlnx,use-s-axi-gp0 = <0x00>;
			xlnx,use-s-axi-gp1 = <0x00>;
			xlnx,pcw-i2c0-peripheral-enable = <0x00>;
			xlnx,pcw-uiparam-ddr-dq-2-length-mm = <0x00>;
			xlnx,pcw-nor-grp-sram-cs0-io = "<Select>";
			xlnx,pcw-enet1-grp-mdio-io = "<Select>";
			xlnx,pcw-enet0-peripheral-enable = <0x00>;
			xlnx,pcw-p2f-usb0-intr = <0x00>;
			xlnx,pcw-enet1-reset-io = "<Select>";
			xlnx,pcw-mio-46-direction = "<Select>";
			xlnx,pcw-spi1-grp-ss2-enable = <0x00>;
			xlnx,pcw-nor-grp-a25-io = "<Select>";
			xlnx,pcw-en-emio-can0 = <0x00>;
			xlnx,pcw-core1-fiq-intr = <0x00>;
			xlnx,s-axi-hp2-id-width = <0x06>;
			xlnx,pcw-en-emio-can1 = <0x00>;
			xlnx,pcw-mio-2-iotype = "<Select>";
			xlnx,pcw-use-dma0 = <0x00>;
			xlnx,pcw-can1-grp-clk-enable = <0x00>;
			xlnx,pcw-mio-38-iotype = "<Select>";
			xlnx,pcw-use-dma1 = <0x00>;
			xlnx,pcw-use-dma2 = <0x00>;
			xlnx,pcw-use-dma3 = <0x00>;
			xlnx,pcw-usb-reset-select = "<Select>";
			xlnx,pcw-mio-7-slew = "<Select>";
			xlnx,pcw-ttc1-peripheral-enable = <0x01>;
			xlnx,use-axi-nonsecure = <0x00>;
			xlnx,pcw-sd0-grp-pow-enable = <0x00>;
			xlnx,pcw-mio-4-slew = "<Select>";
			xlnx,pcw-mio-25-pullup = "<Select>";
			xlnx,pcw-uiparam-ddr-dqs-0-propogation-delay = <0xa0>;
			xlnx,pcw-mio-1-slew = "<Select>";
			xlnx,pcw-trace-grp-32bit-io = "<Select>";
			xlnx,pcw-act-ttc1-clk2-peripheral-freqmhz = <0x69f6bcb>;
			xlnx,pcw-spi-peripheral-valid = <0x00>;
			xlnx,pcw-mio-15-direction = "<Select>";
			xlnx,pcw-act-enet1-peripheral-freqmhz = <0x0a>;
			xlnx,pcw-en-ptp-enet0 = <0x00>;
			xlnx,pcw-mio-13-iotype = "<Select>";
			xlnx,pcw-en-ptp-enet1 = <0x00>;
			xlnx,pcw-mio-5-pullup = "<Select>";
			xlnx,pcw-en-clk3-port = <0x00>;
			xlnx,pcw-mio-42-pullup = "enabled";
			xlnx,pcw-sd1-grp-wp-io = "<Select>";
			xlnx,pcw-fpga-fclk3-enable = <0x00>;
			xlnx,pcw-mio-2-direction = "<Select>";
			xlnx,pcw-p2f-dmac6-intr = <0x00>;
			xlnx,pcw-en-clk0-port = <0x01>;
			xlnx,pcw-s-axi-gp1-id-width = <0x06>;
			xlnx,pcw-p2f-dmac3-intr = <0x00>;
			xlnx,s-axi-acp-awuser-val = <0x1f>;
			xlnx,pcw-uiparam-ddr-clock-2-length-mm = <0x00>;
			xlnx,pcw-p2f-dmac0-intr = <0x00>;
			xlnx,pcw-uiparam-ddr-bank-addr-count = <0x03>;
			xlnx,edk-iptype = "PERIPHERAL";
			xlnx,pcw-en-emio-gpio = <0x01>;
			xlnx,pcw-act-apu-peripheral-freqmhz = <0x27bc86bf>;
			xlnx,pcw-trace-internal-width = <0x02>;
			xlnx,pcw-mio-25-direction = "<Select>";
			xlnx,pcw-act-fpga2-peripheral-freqmhz = <0x0a>;
			xlnx,pcw-uiparam-ddr-row-addr-count = <0x0f>;
			xlnx,pcw-trace-grp-32bit-enable = <0x00>;
			xlnx,pcw-nor-cs0-t-pc = <0x01>;
			xlnx,en-emio-enet0 = <0x00>;
			xlnx,pcw-mio-29-iotype = "<Select>";
			xlnx,pcw-mio-30-iotype = "<Select>";
			xlnx,en-emio-enet1 = <0x00>;
			xlnx,pcw-nor-cs0-we-time = <0x00>;
			xlnx,use-s-axi-hp0 = <0x01>;
			xlnx,use-s-axi-hp1 = <0x00>;
			xlnx,use-s-axi-hp2 = <0x00>;
			xlnx,use-s-axi-hp3 = <0x00>;
			xlnx,pcw-enet1-peripheral-clksrc = "IO , PLL";
			xlnx,pcw-s-axi-hp1-id-width = <0x06>;
			xlnx,pcw-uiparam-ddr-dq-3-package-length = <0x6329028>;
			xlnx,pcw-mio-16-pullup = "<Select>";
			xlnx,pcw-trace-trace-io = "<Select>";
			xlnx,pcw-use-trace = <0x00>;
			xlnx,pcw-cpu-cpu-6x4x-max-range = <0x2ff>;
			xlnx,pcw-p2f-enet1-intr = <0x00>;
			xlnx,pcw-nor-cs0-t-rc = <0x0b>;
			xlnx,pcw-single-qspi-data-mode = "<Select>";
			xlnx,pcw-uiparam-ddr-dqs-0-length-mm = <0x00>;
			xlnx,pcw-uiparam-ddr-dqs-0-package-length = <0x6430700>;
			xlnx,pcw-mio-35-direction = "<Select>";
			xlnx,pcw-gpio-mio-gpio-enable = <0x00>;
			xlnx,pcw-spi0-grp-ss0-enable = <0x00>;
			xlnx,fclk-clk0-buf;
			xlnx,pcw-mio-9-iotype = "<Select>";
			xlnx,pcw-m-axi-gp0-enable-static-remap = <0x00>;
			xlnx,pcw-mio-46-iotype = "<Select>";
			xlnx,pcw-nand-cycles-t-rea = <0x01>;
			xlnx,pcw-act-usb1-peripheral-freqmhz = <0x3c>;
			compatible = "xlnx,processing-system7-5.5";
			xlnx,pcw-fclk3-peripheral-clksrc = "IO , PLL";
			xlnx,pcw-preset-bank0-voltage = "LVCMOS , 3.3V";
			xlnx,pcw-nor-grp-cs0-enable = <0x00>;
			xlnx,pcw-mio-33-pullup = "<Select>";
			xlnx,pcw-trace-pipeline-width = <0x08>;
			xlnx,pcw-ftm-cti-in0 = "<Select>";
			xlnx,pcw-ftm-cti-in1 = "<Select>";
			xlnx,pcw-ftm-cti-in2 = "<Select>";
			xlnx,pcw-ftm-cti-in3 = "<Select>";
			xlnx,pcw-uiparam-ddr-dq-1-length-mm = <0x00>;
			xlnx,pcw-mio-45-direction = "inout";
			xlnx,pcw-uart-peripheral-divisor0 = <0x12>;
			xlnx,use-m-axi-gp0 = <0x01>;
			xlnx,pcw-mio-primitive = <0x36>;
			xlnx,pcw-ddr-priority-readport-0 = "<Select>";
			xlnx,use-m-axi-gp1 = <0x00>;
			xlnx,pcw-ddr-priority-readport-1 = "<Select>";
			xlnx,pcw-ddr-priority-readport-2 = "<Select>";
			xlnx,pcw-en-pjtag = <0x00>;
			xlnx,pcw-fclk0-peripheral-divisor0 = <0x06>;
			xlnx,pcw-nor-cs0-t-tr = <0x01>;
			xlnx,pcw-ddr-priority-readport-3 = "<Select>";
			xlnx,pcw-fclk0-peripheral-divisor1 = <0x03>;
			xlnx,pcw-gpio-emio-gpio-io = <0x20>;
			xlnx,pcw-smc-peripheral-valid = <0x00>;
			xlnx,pcw-uart1-peripheral-enable = <0x01>;
			xlnx,pcw-act-smc-peripheral-freqmhz = <0x0a>;
			xlnx,pcw-m-axi-gp1-enable-static-remap = <0x00>;
			xlnx,pcw-mio-21-iotype = "<Select>";
			xlnx,pcw-mio-49-pullup = "enabled";
			xlnx,pcw-mio-50-pullup = "<Select>";
			xlnx,pcw-p2f-cti-intr = <0x00>;
			xlnx,pcw-mio-tree-signals = "unassigned#unassigned#unassigned#unassigned#unassigned#unassigned#unassigned#unassigned#unassigned#unassigned#unassigned#unassigned#unassigned#unassigned#unassigned#unassigned#unassigned#unassigned#unassigned#unassigned#unassigned#unassigned#unassigned#unassigned#unassigned#unassigned#unassigned#unassigned#unassigned#unassigned#unassigned#unassigned#unassigned#unassigned#unassigned#unassigned#unassigned#unassigned#unassigned#unassigned#clk#cmd#data[0]#data[1]#data[2]#data[3]#unassigned#unassigned#tx#rx#unassigned#unassigned#unassigned#unassigned";
			xlnx,pcw-nor-cs0-t-wc = <0x0b>;
			xlnx,pcw-p2f-smc-intr = <0x00>;
			xlnx,pcw-qspi-grp-ss1-enable = <0x00>;
			xlnx,pcw-s-axi-hp2-freqmhz = <0x0a>;
			xlnx,pcw-spi0-grp-ss2-io = "<Select>";
			xlnx,pcw-uiparam-ddr-col-addr-count = <0x0a>;
			xlnx,pcw-ddr-lpr-to-critical-priority-level = <0x02>;
			xlnx,pcw-armpll-ctrl-fbdiv = <0x28>;
			xlnx,pcw-spi1-grp-ss1-enable = <0x00>;
			xlnx,pcw-en-emio-pjtag = <0x00>;
			xlnx,pcw-uiparam-ddr-high-temp = "Normal , (0-85)";
			xlnx,pcw-uiparam-ddr-dqs-3-propogation-delay = <0xa0>;
			xlnx,pcw-nor-cs0-t-wp = <0x01>;
			xlnx,pcw-trace-grp-2bit-enable = <0x00>;
			xlnx,pcw-ttc0-clk2-peripheral-freqmhz = <0x7f28155>;
			xlnx,pcw-mio-1-iotype = "<Select>";
			xlnx,pcw-mio-37-iotype = "<Select>";
			xlnx,pcw-use-cross-trigger = <0x00>;
			xlnx,pcw-mio-14-direction = "<Select>";
			xlnx,pcw-s-axi-acp-freqmhz = <0x0a>;
			xlnx,pcw-fclk1-peripheral-divisor0 = <0x09>;
			xlnx,pcw-fclk1-peripheral-divisor1 = <0x01>;
			xlnx,pcw-ttc0-ttc0-io = "EMIO";
			xlnx,pcw-spi1-grp-ss2-io = "<Select>";
			xlnx,pcw-ttc1-clk2-peripheral-clksrc = "CPU_1X";
			xlnx,pcw-sd0-grp-wp-io = "<Select>";
			xlnx,pcw-i2c-reset-polarity = "Active , Low";
			xlnx,pcw-mio-24-pullup = "<Select>";
			xlnx,pcw-ddr-hprlpr-queue-partition = "HPR(0)/LPR(32)";
			xlnx,pcw-apu-peripheral-freqmhz = <0x27bc86aa>;
			xlnx,pcw-mio-1-direction = "<Select>";
			xlnx,pcw-tpiu-peripheral-clksrc = "External";
			xlnx,pcw-core0-irq-intr = <0x00>;
			xlnx,pcw-uiparam-ddr-memory-type = "DDR , 3";
			xlnx,pcw-uiparam-ddr-clock-1-length-mm = <0x00>;
			xlnx,s-axi-acp-id-width = <0x03>;
			xlnx,pcw-mio-24-direction = "<Select>";
			xlnx,pcw-gpio-emio-gpio-width = <0x20>;
			xlnx,pcw-uiparam-ddr-clock-1-propogation-delay = <0xa0>;
			xlnx,irq-f2p-mode = "DIRECT";
			xlnx,pcw-mio-12-iotype = "<Select>";
			xlnx,pcw-mio-4-pullup = "<Select>";
			xlnx,pcw-mio-41-pullup = "enabled";
			xlnx,pcw-clk3-freq = <0x989680>;
			xlnx,pcw-can1-peripheral-enable = <0x00>;
			xlnx,pcw-fclk2-peripheral-divisor0 = <0x01>;
			xlnx,pcw-mio-51-slew = "<Select>";
			xlnx,pcw-fclk2-peripheral-divisor1 = <0x01>;
			xlnx,pcw-fpga-fclk2-enable = <0x00>;
			xlnx,pcw-clk0-freq = <0x5f5e100>;
			xlnx,pcw-mio-47-slew = "slow";
			xlnx,pcw-sdio-peripheral-divisor0 = <0x12>;
			xlnx,pcw-use-expanded-iop = <0x00>;
			xlnx,pcw-mio-44-slew = "slow";
			xlnx,pcw-qspi-peripheral-divisor0 = <0x01>;
			xlnx,pcw-gp0-num-read-threads = <0x04>;
			xlnx,pcw-en-rst3-port = <0x00>;
			xlnx,pcw-mio-34-direction = "<Select>";
			xlnx,pcw-mio-41-slew = "slow";
			xlnx,pcw-tpiu-peripheral-divisor0 = <0x01>;
			xlnx,pcw-en-rst0-port = <0x01>;
			xlnx,pcw-mio-28-iotype = "<Select>";
			xlnx,pcw-mio-37-slew = "<Select>";
			xlnx,pcw-sd1-grp-pow-enable = <0x00>;
			xlnx,pcw-mio-34-slew = "<Select>";
			xlnx,pcw-en-emio-sram-int = <0x00>;
			xlnx,pcw-uiparam-ddr-dqs-to-clk-delay-0 = <0x00>;
			xlnx,pcw-uiparam-ddr-dqs-to-clk-delay-1 = <0x00>;
			xlnx,pcw-uiparam-ddr-dqs-to-clk-delay-2 = <0x00>;
			xlnx,pcw-uiparam-ddr-dqs-to-clk-delay-3 = <0x00>;
			xlnx,pcw-mio-31-slew = "<Select>";
			xlnx,pcw-sd1-grp-wp-enable = <0x00>;
			xlnx,pcw-mio-15-pullup = "<Select>";
			xlnx,pcw-fclk3-peripheral-divisor0 = <0x01>;
			xlnx,pcw-fclk3-peripheral-divisor1 = <0x01>;
			xlnx,pcw-uiparam-ddr-dq-0-length-mm = <0x00>;
			xlnx,pcw-mio-27-slew = "<Select>";
			xlnx,pcw-smc-peripheral-freqmhz = <0x64>;
			xlnx,pcw-num-f2p-intr-inputs = <0x04>;
			xlnx,pcw-wdt-wdt-io = "<Select>";
			xlnx,pcw-uiparam-ddr-dq-0-propogation-delay = <0xa0>;
			xlnx,pcw-mio-24-slew = "<Select>";
			xlnx,pcw-mio-44-direction = "inout";
			xlnx,pcw-fpga0-peripheral-freqmhz = <0x64>;
			xlnx,pcw-mio-8-iotype = "<Select>";
			xlnx,pcw-iopll-ctrl-fbdiv = <0x36>;
			xlnx,pcw-mio-45-iotype = "LVCMOS , 1.8V";
			xlnx,pcw-p2f-can1-intr = <0x00>;
			xlnx,pcw-ddr-priority-writeport-0 = "<Select>";
			xlnx,pcw-i2c0-reset-io = "<Select>";
			xlnx,pcw-ddr-priority-writeport-1 = "<Select>";
			xlnx,pcw-ddr-priority-writeport-2 = "<Select>";
			xlnx,pcw-mio-21-slew = "<Select>";
			xlnx,pcw-ddr-priority-writeport-3 = "<Select>";
			xlnx,pcw-en-can0 = <0x00>;
			xlnx,pcw-mio-17-slew = "<Select>";
			xlnx,pcw-en-can1 = <0x00>;
			xlnx,pcw-fpga3-peripheral-freqmhz = <0x32>;
			xlnx,pcw-trace-grp-16bit-io = "<Select>";
			xlnx,pcw-cpu-peripheral-divisor0 = <0x02>;
			xlnx,pcw-m-axi-gp1-support-narrow-burst = <0x00>;
			xlnx,pcw-mio-32-pullup = "<Select>";
			xlnx,pcw-usb0-peripheral-enable = <0x00>;
			xlnx,pcw-mio-14-slew = "<Select>";
			xlnx,pcw-uiparam-ddr-train-read-gate = <0x01>;
			xlnx,gp1-en-modifiable-txn = <0x01>;
			xlnx,name = "processing_system7_0";
			xlnx,pcw-act-spi-peripheral-freqmhz = <0x0a>;
			xlnx,pcw-mio-11-slew = "<Select>";
			xlnx,pcw-ttc1-clk1-peripheral-freqmhz = <0x7f28155>;
			xlnx,pcw-en-emio-modem-uart0 = <0x00>;
			xlnx,pcw-dq-width = <0x20>;
			xlnx,pcw-en-emio-modem-uart1 = <0x00>;
			xlnx,pcw-sd0-peripheral-enable = <0x01>;
			xlnx,pcw-nor-grp-cs0-io = "<Select>";
			xlnx,pcw-can-peripheral-valid = <0x00>;
			xlnx,pcw-m-axi-gp1-id-width = <0x0c>;
			xlnx,pcw-ttc0-clk0-peripheral-clksrc = "CPU_1X";
			xlnx,pcw-act-ttc0-clk1-peripheral-freqmhz = <0x69f6bcb>;
			xlnx,pcw-mio-19-iotype = "<Select>";
			xlnx,pcw-mio-20-iotype = "<Select>";
			xlnx,pcw-wdt-peripheral-enable = <0x00>;
			xlnx,pcw-mio-13-direction = "<Select>";
			xlnx,pcw-enet1-grp-mdio-enable = <0x00>;
			xlnx,pcw-mio-48-pullup = "enabled";
			xlnx,pcw-sdio-peripheral-clksrc = "IO , PLL";
			xlnx,pcw-p2f-dmac-abort-intr = <0x00>;
			xlnx,pcw-nor-peripheral-enable = <0x00>;
			xlnx,pcw-en-sdio0 = <0x01>;
			xlnx,pcw-ddr-peripheral-divisor0 = <0x02>;
			xlnx,pcw-en-sdio1 = <0x00>;
			xlnx,pcw-mio-0-direction = "<Select>";
			xlnx,pcw-uiparam-ddr-dqs-1-package-length = <0x3fcdfc0>;
			xlnx,pcw-uiparam-ddr-enable = <0x01>;
			xlnx,pcw-spi1-grp-ss0-enable = <0x00>;
			xlnx,pcw-usb-reset-polarity = "Active , Low";
			xlnx,pcw-fclk-clk2-buf;
			xlnx,pcw-p2f-uart0-intr = <0x00>;
			xlnx,pcw-uiparam-ddr-t-rcd = <0x07>;
			xlnx,ps7-si-rev = "PRODUCTION";
			xlnx,pcw-mio-0-iotype = "<Select>";
			xlnx,pcw-uiparam-ddr-clock-0-length-mm = <0x00>;
			xlnx,pcw-mio-36-iotype = "<Select>";
			xlnx,pcw-act-can1-peripheral-freqmhz = <0x16b4ddc>;
			xlnx,pcw-cpu-cpu-pll-freqmhz = <0x4f790c08>;
			xlnx,pcw-mio-23-direction = "<Select>";
			xlnx,pcw-uiparam-ddr-train-write-level = <0x01>;
			xlnx,pcw-ddr-write-to-critical-priority-level = <0x02>;
			xlnx,pcw-nand-peripheral-enable = <0x00>;
			xlnx,pcw-en-gpio = <0x00>;
			xlnx,pcw-spi0-spi0-io = "<Select>";
			xlnx,pcw-use-high-ocm = <0x00>;
			xlnx,pcw-en-emio-sdio0 = <0x00>;
			xlnx,pcw-mio-23-pullup = "<Select>";
			xlnx,pcw-en-emio-sdio1 = <0x00>;
			xlnx,pcw-gp1-en-modifiable-txn = <0x01>;
			xlnx,pcw-mio-9-direction = "<Select>";
			xlnx,pcw-uart-peripheral-clksrc = "IO , PLL";
			xlnx,pcw-en-clktrig3-port = <0x00>;
			xlnx,pcw-qspi-peripheral-clksrc = "IO , PLL";
			xlnx,pcw-uiparam-ddr-board-delay0 = <0x3d090>;
			xlnx,pcw-uiparam-ddr-board-delay1 = <0x3d090>;
			xlnx,pcw-uiparam-ddr-board-delay2 = <0x3d090>;
			xlnx,pcw-mio-53-iotype = "<Select>";
			xlnx,pcw-uiparam-ddr-board-delay3 = <0x3d090>;
			xlnx,pcw-en-clktrig0-port = <0x00>;
			xlnx,pcw-dm-width = <0x04>;
			xlnx,pcw-i2c0-i2c0-io = "<Select>";
			xlnx,pcw-mio-33-direction = "<Select>";
			xlnx,pcw-mio-11-iotype = "<Select>";
			xlnx,pcw-mio-3-pullup = "<Select>";
			xlnx,fclk-clk3-buf;
			xlnx,pcw-mio-39-pullup = "<Select>";
			xlnx,pcw-mio-40-pullup = "enabled";
			xlnx,pcw-uart0-grp-full-io = "<Select>";
			xlnx,pcw-fpga-fclk1-enable = <0x01>;
			xlnx,pcw-ttc0-peripheral-enable = <0x01>;
			xlnx,pcw-uiparam-ddr-t-rc = <0x2ea4eb0>;
			xlnx,pcw-uiparam-ddr-adv-enable = <0x00>;
			xlnx,pcw-i2c-reset-enable = <0x00>;
			xlnx,pcw-s-axi-hp1-freqmhz = <0x0a>;
			xlnx,use-default-acp-user-val = <0x00>;
			xlnx,pcw-act-i2c-peripheral-freqmhz = <0x32>;
			xlnx,pcw-uiparam-ddr-t-faw = <0x28>;
			xlnx,preset = "None";
			xlnx,pcw-use-proc-event-bus = <0x00>;
			xlnx,pcw-uiparam-ddr-t-rp = <0x07>;
			xlnx,pcw-p2f-sdio0-intr = <0x00>;
			xlnx,pcw-mio-43-direction = "inout";
			xlnx,s-axi-hp3-id-width = <0x06>;
			xlnx,pcw-mio-27-iotype = "<Select>";
			xlnx,pcw-uiparam-ddr-dq-3-propogation-delay = <0xa0>;
			xlnx,pcw-p2f-spi1-intr = <0x00>;
			xlnx,pcw-spi-peripheral-freqmhz = <0x9ef21aa>;
			xlnx,m-axi-gp0-thread-id-width = <0x0c>;
			xlnx,s-axi-gp0-id-width = <0x06>;
			xlnx,pcw-mio-14-pullup = "<Select>";
			xlnx,pcw-mio-9-slew = "<Select>";
			xlnx,m-axi-gp0-enable-static-remap = <0x00>;
			xlnx,pcw-mio-53-direction = "<Select>";
			xlnx,pcw-mio-6-slew = "<Select>";
			xlnx,pcw-mio-7-iotype = "<Select>";
			xlnx,pcw-mio-44-iotype = "LVCMOS , 1.8V";
			xlnx,pcw-use-fabric-interrupt = <0x01>;
			xlnx,pcw-act-ttc1-clk0-peripheral-freqmhz = <0x69f6bcb>;
			xlnx,pcw-mio-3-slew = "<Select>";
			xlnx,pcw-sd1-grp-cd-io = "<Select>";
			xlnx,pcw-use-s-axi-gp0 = <0x00>;
			xlnx,pcw-use-s-axi-gp1 = <0x00>;
			xlnx,pcw-en-usb0 = <0x00>;
			xlnx,pcw-mio-0-slew = "<Select>";
			xlnx,pcw-nor-grp-sram-int-io = "<Select>";
			xlnx,pcw-en-usb1 = <0x00>;
			xlnx,pcw-mio-12-direction = "<Select>";
			xlnx,pcw-pjtag-peripheral-enable = <0x00>;
			xlnx,pcw-pcap-peripheral-clksrc = "IO , PLL";
			xlnx,pcw-m-axi-gp1-thread-id-width = <0x0c>;
			xlnx,pcw-mio-31-pullup = "<Select>";
			xlnx,pcw-usb-reset-enable = <0x00>;
			xlnx,pcw-mio-tree-peripherals = "unassigned#unassigned#unassigned#unassigned#unassigned#unassigned#unassigned#unassigned#unassigned#unassigned#unassigned#unassigned#unassigned#unassigned#unassigned#unassigned#unassigned#unassigned#unassigned#unassigned#unassigned#unassigned#unassigned#unassigned#unassigned#unassigned#unassigned#unassigned#unassigned#unassigned#unassigned#unassigned#unassigned#unassigned#unassigned#unassigned#unassigned#unassigned#unassigned#unassigned#SD , 0#SD , 0#SD , 0#SD , 0#SD , 0#SD , 0#unassigned#unassigned#UART , 1#UART , 1#unassigned#unassigned#unassigned#unassigned";
			xlnx,s-axi-hp0-id-width = <0x06>;
			xlnx,include-trace-buffer = <0x00>;
			xlnx,pcw-use-cr-fabric = <0x01>;
			xlnx,pcw-enet0-peripheral-clksrc = "IO , PLL";
			xlnx,package-name = "clg400";
			xlnx,m-axi-gp1-enable-static-remap = <0x00>;
			xlnx,pcw-en-clk2-port = <0x00>;
			xlnx,pcw-p2f-dmac5-intr = <0x00>;
			xlnx,pcw-mio-18-iotype = "<Select>";
			xlnx,pcw-mio-22-direction = "<Select>";
			xlnx,pcw-mio-47-pullup = "enabled";
			xlnx,pcw-apu-clk-ratio-enable = "6:2:1";
			xlnx,pcw-act-fpga0-peripheral-freqmhz = <0x64>;
			xlnx,pcw-p2f-dmac2-intr = <0x00>;
			xlnx,pcw-fclk2-peripheral-clksrc = "IO , PLL";
			xlnx,pcw-usb1-usb1-io = "<Select>";
			xlnx,ip-name = "processing_system7";
			xlnx,pcw-mio-8-direction = "<Select>";
			xlnx,pcw-s-axi-hp2-id-width = <0x06>;
			xlnx,pcw-act-fpga3-peripheral-freqmhz = <0x0a>;
			xlnx,pcw-qspi-grp-fbclk-enable = <0x00>;
			xlnx,pcw-qspi-grp-io1-io = "<Select>";
			xlnx,pcw-trace-buffer-fifo-size = <0x80>;
			xlnx,pcw-use-trace-data-edge-detector = <0x00>;
			xlnx,pcw-mio-35-iotype = "<Select>";
			xlnx,pcw-sd1-sd1-io = "<Select>";
			xlnx,pcw-en-enet0 = <0x00>;
			xlnx,pcw-en-enet1 = <0x00>;
			xlnx,pcw-mio-32-direction = "<Select>";
			xlnx,pcw-sd0-grp-wp-enable = <0x00>;
			xlnx,include-acp-trans-check = <0x00>;
			xlnx,pcw-i2c-peripheral-freqmhz = <0x19>;
			xlnx,pcw-uart0-peripheral-enable = <0x00>;
			xlnx,pcw-p2f-enet0-intr = <0x00>;
			xlnx,pcw-spi0-grp-ss1-io = "<Select>";
			xlnx,pcw-mio-22-pullup = "<Select>";
			xlnx,pcw-can0-can0-io = "<Select>";
			xlnx,pcw-s-axi-gp1-freqmhz = <0x0a>;
			xlnx,pcw-en-ddr = <0x01>;
			xlnx,pcw-qspi-internal-highaddress = <0xfcffffff>;
			xlnx,pcw-mio-52-iotype = "<Select>";
			xlnx,pcw-en-emio-enet0 = <0x00>;
			xlnx,pcw-uiparam-ddr-clock-0-package-length = <0x4cb9f7c>;
			xlnx,pcw-en-emio-enet1 = <0x00>;
			xlnx,pcw-uiparam-ddr-dqs-2-propogation-delay = <0xa0>;
			xlnx,pcw-mio-42-direction = "inout";
			xlnx,pcw-use-s-axi-hp0 = <0x01>;
			xlnx,pcw-use-s-axi-hp1 = <0x00>;
			xlnx,pcw-enet0-peripheral-divisor0 = <0x01>;
			xlnx,pcw-mio-10-iotype = "<Select>";
			xlnx,pcw-use-s-axi-hp2 = <0x00>;
			xlnx,pcw-enet0-peripheral-divisor1 = <0x01>;
			xlnx,pcw-mio-2-pullup = "<Select>";
			xlnx,pcw-use-s-axi-hp3 = <0x00>;
			xlnx,pcw-mio-38-pullup = "<Select>";
			xlnx,pcw-spi1-grp-ss1-io = "<Select>";
			xlnx,pcw-fpga-fclk0-enable = <0x01>;
			xlnx,pcw-uiparam-ddr-dqs-2-package-length = <0x550a62c>;
			xlnx,pcw-p2f-qspi-intr = <0x00>;
			xlnx,pcw-ttc1-clk1-peripheral-clksrc = "CPU_1X";
			xlnx,pcw-gp1-num-write-threads = <0x04>;
			xlnx,pcw-fclk-clk0-buf;
			xlnx,pcw-uiparam-ddr-use-internal-vref = <0x00>;
			xlnx,trace-buffer-clock-delay = <0x0c>;
			xlnx,pcw-en-4k-timer = <0x00>;
			xlnx,pcw-p2f-i2c1-intr = <0x00>;
			xlnx,pcw-mio-52-direction = "<Select>";
			xlnx,pcw-override-basic-clock = <0x00>;
			xlnx,pcw-mio-26-iotype = "<Select>";
			xlnx,dq-width = <0x20>;
			xlnx,pcw-s-axi-hp0-data-width = <0x20>;
			xlnx,pcw-en-emio-i2c0 = <0x00>;
			xlnx,pcw-ttc0-clk0-peripheral-freqmhz = <0x7f28155>;
			xlnx,pcw-en-emio-i2c1 = <0x00>;
			xlnx,use-s-axi-acp = <0x00>;
			xlnx,pcw-sd0-grp-cd-io = "<Select>";
			xlnx,pcw-uiparam-ddr-clock-0-propogation-delay = <0xa0>;
			xlnx,pcw-pcap-peripheral-freqmhz = <0xc8>;
			xlnx,pcw-act-dci-peripheral-freqmhz = <0x9b028a>;
			xlnx,pcw-mio-11-direction = "<Select>";
			xlnx,pcw-enet1-peripheral-divisor0 = <0x01>;
			xlnx,pcw-use-default-acp-user-val = <0x00>;
			xlnx,pcw-ddrpll-ctrl-fbdiv = <0x20>;
			xlnx,pcw-enet1-peripheral-divisor1 = <0x01>;
			xlnx,pcw-mio-13-pullup = "<Select>";
			xlnx,pcw-ps7-si-rev = "PRODUCTION";
			xlnx,pcw-can0-peripheral-enable = <0x00>;
			xlnx,pcw-use-m-axi-gp0 = <0x01>;
			xlnx,pcw-en-emio-cd-sdio0 = <0x00>;
			xlnx,pcw-uart0-uart0-io = "<Select>";
			xlnx,pcw-use-m-axi-gp1 = <0x00>;
			xlnx,pcw-en-emio-cd-sdio1 = <0x00>;
			xlnx,pcw-core1-irq-intr = <0x00>;
			xlnx,pcw-mio-6-iotype = "<Select>";
			xlnx,pcw-mio-43-iotype = "LVCMOS , 1.8V";
			xlnx,pcw-i2c1-reset-enable = <0x00>;
			xlnx,pcw-s-axi-hp1-data-width = <0x40>;
			xlnx,pcw-trace-grp-8bit-enable = <0x00>;
			xlnx,dqs-width = <0x04>;
			xlnx,fclk-clk1-buf;
			xlnx,pcw-mio-21-direction = "<Select>";
			xlnx,pcw-mio-29-pullup = "<Select>";
			xlnx,pcw-mio-30-pullup = "<Select>";
			xlnx,trace-internal-width = <0x02>;
			xlnx,pcw-s-axi-hp0-freqmhz = <0x94>;
			xlnx,pcw-mio-7-direction = "<Select>";
			xlnx,pcw-i2c0-reset-enable = <0x00>;
			xlnx,pcw-mio-53-slew = "<Select>";
			xlnx,pcw-sdio-peripheral-freqmhz = <0x64>;
			xlnx,pcw-uart1-uart1-io = "MIO , 48 , .. , 49";
			xlnx,pcw-dqs-width = <0x04>;
			xlnx,pcw-s-axi-hp2-data-width = <0x40>;
			xlnx,pcw-clk2-freq = <0x989680>;
			xlnx,pcw-mio-49-slew = "slow";
			xlnx,pcw-mio-50-slew = "<Select>";
			xlnx,pcw-mio-17-iotype = "<Select>";
			xlnx,pcw-en-emio-ttc0 = <0x01>;
			xlnx,pcw-mio-9-pullup = "<Select>";
			xlnx,pcw-en-emio-ttc1 = <0x01>;
			xlnx,pcw-mio-46-pullup = "<Select>";
			xlnx,pcw-mio-31-direction = "<Select>";
			xlnx,pcw-mio-46-slew = "<Select>";
			xlnx,pcw-sd1-grp-cd-enable = <0x00>;
			xlnx,dm-width = <0x04>;
			xlnx,pcw-i2c0-grp-int-io = "<Select>";
			xlnx,pcw-mio-43-slew = "slow";
			xlnx,pcw-use-axi-fabric-idle = <0x00>;
			xlnx,pcw-en-rst2-port = <0x00>;
			xlnx,pcw-gpio-emio-gpio-enable = <0x01>;
			xlnx,pcw-mio-39-slew = "<Select>";
			xlnx,pcw-mio-40-slew = "slow";
			xlnx,gp0-en-modifiable-txn = <0x01>;
			xlnx,pcw-uart1-grp-full-io = "<Select>";
			xlnx,pcw-uart-peripheral-valid = <0x01>;
			xlnx,pcw-mio-36-slew = "<Select>";
			xlnx,pcw-uiparam-ddr-dq-0-package-length = <0x5df0958>;
			xlnx,pcw-s-axi-hp3-data-width = <0x40>;
			xlnx,pcw-enet0-peripheral-freqmhz = "1000 , Mbps";
			xlnx,trace-pipeline-width = <0x08>;
			xlnx,m-axi-gp0-id-width = <0x0c>;
			xlnx,pcw-mio-33-slew = "<Select>";
			xlnx,pcw-mio-34-iotype = "<Select>";
			xlnx,pcw-use-coresight = <0x00>;
			xlnx,pcw-uiparam-ddr-bus-width = "16 , Bit";
			xlnx,pcw-en-emio-spi0 = <0x00>;
			xlnx,pcw-en-emio-spi1 = <0x00>;
			xlnx,pcw-i2c1-reset-io = "<Select>";
			xlnx,pcw-mio-29-slew = "<Select>";
			xlnx,pcw-mio-30-slew = "<Select>";
			xlnx,pcw-mio-41-direction = "inout";
			xlnx,pcw-use-debug = <0x00>;
			xlnx,pcw-smc-peripheral-divisor0 = <0x01>;
			xlnx,pcw-i2c1-grp-int-io = "<Select>";
			xlnx,pcw-mio-26-slew = "<Select>";
			xlnx,pcw-s-axi-acp-aruser-val = <0x1f>;
			xlnx,pcw-uiparam-ddr-t-ras-min = <0x23>;
			xlnx,pcw-can1-peripheral-clksrc = "External";
			xlnx,pcw-irq-f2p-mode = "DIRECT";
			xlnx,pcw-mio-21-pullup = "<Select>";
			xlnx,pcw-usb0-reset-io = "<Select>";
			xlnx,pcw-mio-23-slew = "<Select>";
			xlnx,pcw-uiparam-ddr-train-data-eye = <0x01>;
			xlnx,pcw-p2f-can0-intr = <0x00>;
			xlnx,pcw-fpga1-peripheral-freqmhz = <0x8d9ee20>;
			xlnx,pcw-s-axi-acp-id-width = <0x03>;
			xlnx,pcw-smc-peripheral-clksrc = "IO , PLL";
			xlnx,pcw-mio-19-slew = "<Select>";
			xlnx,pcw-mio-20-slew = "<Select>";
			xlnx,pcw-nand-grp-d8-enable = <0x00>;
			xlnx,pcw-nor-sram-cs1-t-pc = <0x01>;
			xlnx,pcw-mio-51-iotype = "<Select>";
			xlnx,pcw-enet-reset-select = "<Select>";
			xlnx,pcw-mio-16-slew = "<Select>";
			xlnx,pcw-dci-peripheral-freqmhz = <0x9b0398>;
			xlnx,pcw-mio-13-slew = "<Select>";
			xlnx,pcw-mio-51-direction = "<Select>";
			xlnx,pcw-mio-1-pullup = "<Select>";
			xlnx,pcw-mio-10-slew = "<Select>";
			xlnx,pcw-mio-37-pullup = "<Select>";
			xlnx,pcw-nor-sram-cs1-t-rc = <0x0b>;
			xlnx,pcw-ttc1-clk2-peripheral-freqmhz = <0x7f28155>;
			xlnx,pcw-mio-10-direction = "<Select>";
			xlnx,pcw-uiparam-ddr-clock-3-propogation-delay = <0xa0>;
			xlnx,pcw-use-ddr-bypass = <0x00>;
			xlnx,pcw-en-modem-uart0 = <0x00>;
			xlnx,pcw-en-modem-uart1 = <0x00>;
			xlnx,pcw-trace-grp-16bit-enable = <0x00>;
			xlnx,pcw-uiparam-ddr-freq-mhz = <0x1fca0555>;
			xlnx,pcw-gp0-en-modifiable-txn = <0x01>;
			xlnx,pcw-nor-sram-cs1-we-time = <0x00>;
			xlnx,pcw-act-ttc0-clk2-peripheral-freqmhz = <0x69f6bcb>;
			xlnx,pcw-uiparam-ddr-ecc = "Disabled";
			xlnx,pcw-mio-25-iotype = "<Select>";
			xlnx,pcw-act-pcap-peripheral-freqmhz = <0xc8>;
			xlnx,pcw-uart1-grp-full-enable = <0x00>;
			xlnx,pcw-ddr-peripheral-clksrc = "DDR , PLL";
			xlnx,pcw-mio-19-direction = "<Select>";
			xlnx,pcw-mio-20-direction = "<Select>";
			xlnx,pcw-mio-12-pullup = "<Select>";
			xlnx,en-emio-trace = <0x00>;
			xlnx,pcw-nor-sram-cs1-t-tr = <0x01>;
			xlnx,pcw-nor-nor-io = "<Select>";
			xlnx,pcw-s-axi-gp0-freqmhz = <0x0a>;
			xlnx,pcw-spi-peripheral-divisor0 = <0x01>;
			xlnx,pcw-trace-buffer-clock-delay = <0x0c>;
			xlnx,pcw-uiparam-ddr-clock-1-package-length = <0x4cb9f7c>;
			xlnx,pcw-mio-5-iotype = "<Select>";
			xlnx,pcw-mio-6-direction = "<Select>";
			xlnx,pcw-mio-42-iotype = "LVCMOS , 1.8V";
			xlnx,pcw-s-axi-acp-awuser-val = <0x1f>;
			xlnx,pcw-use-expanded-ps-slcr-registers = <0x00>;
			xlnx,pcw-uiparam-ddr-cwl = <0x06>;
			xlnx,pcw-spi1-peripheral-enable = <0x00>;
			xlnx,pcw-nor-sram-cs1-t-wc = <0x0b>;
			xlnx,pcw-tpiu-peripheral-freqmhz = <0xc8>;
			xlnx,pcw-pjtag-pjtag-io = "<Select>";
			xlnx,pcw-wdt-peripheral-clksrc = "CPU_1X";
			xlnx,pcw-uiparam-ddr-dq-2-propogation-delay = <0xa0>;
			xlnx,pcw-uiparam-ddr-dqs-3-package-length = <0x6c5db30>;
			xlnx,pcw-mio-28-pullup = "<Select>";
			xlnx,pcw-mio-29-direction = "<Select>";
			xlnx,pcw-mio-30-direction = "<Select>";
			xlnx,pcw-en-clktrig2-port = <0x00>;
			xlnx,pcw-enet0-grp-mdio-enable = <0x00>;
			xlnx,pcw-usb0-peripheral-freqmhz = <0x3c>;
			xlnx,pcw-nor-sram-cs1-t-wp = <0x01>;
			xlnx,pcw-act-ttc-peripheral-freqmhz = <0x32>;
			xlnx,pcw-act-sdio-peripheral-freqmhz = <0x64>;
			xlnx,pcw-import-board-preset = "None";
			xlnx,pcw-mio-16-iotype = "<Select>";
			xlnx,pcw-mio-8-pullup = "<Select>";
			xlnx,pcw-enet0-enet0-io = "<Select>";
			xlnx,pcw-mio-45-pullup = "enabled";
			xlnx,pcw-mio-39-direction = "<Select>";
			xlnx,pcw-mio-40-direction = "inout";
			xlnx,pcw-uiparam-ddr-device-capacity = "4096 , MBits";
			xlnx,pcw-uiparam-ddr-al = <0x00>;
			xlnx,pcw-can-peripheral-divisor0 = <0x01>;
			xlnx,pcw-can-peripheral-divisor1 = <0x01>;
			xlnx,use-trace-data-edge-detector = <0x00>;
			xlnx,pcw-ttc0-clk2-peripheral-clksrc = "CPU_1X";
			xlnx,pcw-nor-cs1-t-ceoe = <0x01>;
			xlnx,pcw-qspi-grp-io1-enable = <0x00>;
			xlnx,s-axi-gp1-id-width = <0x06>;
			xlnx,pcw-uiparam-ddr-bl = <0x08>;
			xlnx,pcw-peripheral-board-preset = "None";
			xlnx,pcw-en-emio-wp-sdio0 = <0x00>;
			xlnx,pcw-p2f-usb1-intr = <0x00>;
			xlnx,pcw-en-emio-wp-sdio1 = <0x00>;
			xlnx,pcw-m-axi-gp1-freqmhz = <0x0a>;
			xlnx,pcw-p2f-spi0-intr = <0x00>;
			xlnx,pcw-sd0-grp-pow-io = "<Select>";
			xlnx,pcw-mio-33-iotype = "<Select>";
			xlnx,pcw-uiparam-ddr-cl = <0x07>;
			xlnx,pcw-ttc1-ttc1-io = "EMIO";
			xlnx,pcw-en-smc = <0x00>;
			xlnx,pcw-fclk-clk3-buf;
			xlnx,pcw-mio-49-direction = "in";
			xlnx,pcw-mio-50-direction = "<Select>";
			xlnx,pcw-enet0-reset-io = "<Select>";
			xlnx,pcw-mio-8-slew = "<Select>";
			xlnx,pcw-mio-19-pullup = "<Select>";
			xlnx,pcw-mio-20-pullup = "<Select>";
			xlnx,pcw-enet1-enet1-io = "<Select>";
			xlnx,pcw-qspi-grp-ss1-io = "<Select>";
			xlnx,pcw-en-i2c0 = <0x00>;
			xlnx,pcw-dci-peripheral-divisor0 = <0x0f>;
			xlnx,pcw-en-i2c1 = <0x00>;
			xlnx,pcw-dci-peripheral-divisor1 = <0x07>;
			xlnx,pcw-mio-5-slew = "<Select>";
			xlnx,pcw-core0-fiq-intr = <0x00>;
			xlnx,s-axi-hp1-id-width = <0x06>;
			xlnx,pcw-fclk1-peripheral-clksrc = "ARM , PLL";
			xlnx,pcw-act-ttc1-clk1-peripheral-freqmhz = <0x69f6bcb>;
			xlnx,pcw-mio-2-slew = "<Select>";
			xlnx,pcw-en-qspi = <0x00>;
			xlnx,pcw-mio-49-iotype = "LVCMOS , 1.8V";
			xlnx,pcw-mio-50-iotype = "<Select>";
			xlnx,pcw-sd1-grp-pow-io = "<Select>";
			xlnx,pcw-en-uart0 = <0x00>;
			xlnx,pcw-i2c1-peripheral-enable = <0x00>;
			xlnx,pcw-en-uart1 = <0x01>;
			xlnx,pcw-ddr-port0-hpr-enable = <0x00>;
			xlnx,pcw-mio-0-pullup = "<Select>";
			xlnx,pcw-enet1-peripheral-enable = <0x00>;
			xlnx,pcw-gpio-mio-gpio-io = "<Select>";
			xlnx,pcw-mio-36-pullup = "<Select>";
			xlnx,pcw-spi0-grp-ss0-io = "<Select>";
			phandle = <0x4c>;
		};

		ps7_pmu@f8891000 {
			compatible = "xlnx,ps7-pmu-1.00.a";
			status = "okay";
			xlnx,ip-name = "ps7_pmu";
			reg = <0xf8891000 0x1000 0xf8893000 0x1000>;
			xlnx,name = "ps7_pmu_0";
			phandle = <0x1a>;
		};

		ps7_ddr@100000 {
			compatible = "xlnx,ps7-ddr-1.00.a";
			status = "okay";
			xlnx,ip-name = "ps7_ddr";
			reg = <0x100000 0x1ff00000>;
			xlnx,name = "ps7_ddr_0";
			phandle = <0x4d>;
		};

		ps7_ocmc@f800c000 {
			compatible = "xlnx,ps7-ocmc-1.00.a";
			status = "okay";
			xlnx,ip-name = "ps7_ocmc";
			reg = <0xf800c000 0x1000>;
			xlnx,name = "ps7_ocmc_0";
			phandle = <0x19>;
		};

		ps7_gpv@f8900000 {
			compatible = "xlnx,ps7-gpv-1.00.a";
			status = "okay";
			xlnx,ip-name = "ps7_gpv";
			reg = <0xf8900000 0x100000>;
			xlnx,name = "ps7_gpv_0";
			phandle = <0x15>;
		};

		ps7_scuc@f8f00000 {
			compatible = "xlnx,ps7-scuc-1.00.a";
			status = "okay";
			xlnx,ip-name = "ps7_scuc";
			reg = <0xf8f00000 0xfd>;
			xlnx,name = "ps7_scuc_0";
			phandle = <0x1b>;
		};

		ps7_iop_bus_config@e0200000 {
			compatible = "xlnx,ps7-iop-bus-config-1.00.a";
			status = "okay";
			xlnx,ip-name = "ps7_iop_bus_config";
			reg = <0xe0200000 0x1000>;
			xlnx,name = "ps7_iop_bus_config_0";
			phandle = <0x17>;
		};

		ps7_ram@0 {
			compatible = "xlnx,ps7-ram-1.00.a";
			status = "okay";
			xlnx,ip-name = "ps7_ram";
			reg = <0x00 0x30000 0x00 0x40000>;
			xlnx,name = "ps7_ram_0";
			phandle = <0x4e>;
		};

		ps7_ram@ffff0000 {
			compatible = "xlnx,ps7-ram-1.00.a";
			status = "okay";
			xlnx,ip-name = "ps7_ram";
			reg = <0xffff0000 0xfe00>;
			xlnx,name = "ps7_ram_1";
			phandle = <0x4f>;
		};

		ps7_dma@f8004000 {
			compatible = "xlnx,ps7-dma-1.00.a";
			status = "okay";
			xlnx,ip-name = "ps7_dma";
			xlnx,is-secure;
			reg = <0xf8004000 0x1000>;
			xlnx,name = "ps7_dma_ns";
			phandle = <0x11>;
		};

		ps7_afi@f8008000 {
			compatible = "xlnx,ps7-afi-1.00.a";
			status = "okay";
			xlnx,ip-name = "ps7_afi";
			reg = <0xf8008000 0x1000>;
			xlnx,name = "ps7_afi_0";
			phandle = <0x0a>;
		};

		ps7_afi@f8009000 {
			compatible = "xlnx,ps7-afi-1.00.a";
			status = "okay";
			xlnx,ip-name = "ps7_afi";
			reg = <0xf8009000 0x1000>;
			xlnx,name = "ps7_afi_1";
			phandle = <0x0b>;
		};

		ps7_afi@f800a000 {
			compatible = "xlnx,ps7-afi-1.00.a";
			status = "okay";
			xlnx,ip-name = "ps7_afi";
			reg = <0xf800a000 0x1000>;
			xlnx,name = "ps7_afi_2";
			phandle = <0x0c>;
		};

		ps7_afi@f800b000 {
			compatible = "xlnx,ps7-afi-1.00.a";
			status = "okay";
			xlnx,ip-name = "ps7_afi";
			reg = <0xf800b000 0x1000>;
			xlnx,name = "ps7_afi_3";
			phandle = <0x0d>;
		};

		ps7_m_axi_gp@40000000 {
			compatible = "xlnx,ps7-m-axi-gp-1.00.a";
			status = "okay";
			xlnx,ip-name = "ps7_m_axi_gp";
			xlnx,is-hierarchy;
			reg = <0x40000000 0x40000000>;
			xlnx,name = "ps7_m_axi_gp0";
			phandle = <0x50>;
		};
	};

	amba_pl {
		ranges;
		compatible = "simple-bus";
		#address-cells = <0x01>;
		#size-cells = <0x01>;
		firmware-name = "top_design_wrapper_02.bit.bin";
		phandle = <0x51>;

		clocking1 {
			compatible = "xlnx,fclk";
			assigned-clocks = <0x24 0x10>;
			assigned-clock-rates = <0x8d9ee20>;
			#clock-cells = <0x00>;
			clock-output-names = "fabric_clk";
			clocks = <0x24 0x10>;
			phandle = <0x52>;
		};

		clocking0 {
			compatible = "xlnx,fclk";
			assigned-clocks = <0x24 0x0f>;
			assigned-clock-rates = <0x5f5e100>;
			#clock-cells = <0x00>;
			clock-output-names = "fabric_clk";
			clocks = <0x24 0x0f>;
			phandle = <0x53>;
		};

		afi0@f8008000 {
			status = "okay";
			compatible = "xlnx,afi-fpga";
			#address-cells = <0x01>;
			reg = <0xf8008000 0x1000>;
			#size-cells = <0x00>;
			xlnx,afi-width = <0x01>;
			phandle = <0x54>;
		};

		misc_clk_0 {
			compatible = "fixed-clock";
			clock-frequency = <0x5f5e100>;
			#clock-cells = <0x00>;
			phandle = <0x32>;
		};

		axi_dynclk@43c10000 {
			xlnx,kversionminor = <0x02>;
			xlnx,kversionmajor = <0x01>;
			xlnx,krefclkfreqhz = <0x5f5e100>;
			compatible = "xlnx,axi-dynclk-1.2";
			status = "okay";
			clock-names = "REF_CLK_I\0s_axi_lite_aclk";
			xlnx,ip-name = "axi_dynclk";
			xlnx,edk-iptype = "PERIPHERAL";
			reg = <0x43c10000 0x10000>;
			clocks = <0x24 0x0f 0x24 0x0f>;
			xlnx,name = "axi_dynclk_0";
			phandle = <0x06>;
		};

		v_frmbuf_rd@43c40000 {
			xlnx,has-y-uv8 = <0x00>;
			xlnx,max-height = <0x438>;
			xlnx,has-bgra8 = <0x00>;
			xlnx,has-rgba8 = <0x00>;
			xlnx,ip-name = "v_frmbuf_rd";
			reg = <0x43c40000 0x10000>;
			xlnx,s-axi-ctrl-addr-width = <0x07>;
			xlnx,pixels-per-clock = <0x01>;
			xlnx,samples-per-clock = <0x01>;
			xlnx,max-nr-planes = <0x01>;
			xlnx,has-bgr8 = <0x00>;
			xlnx,has-rgb8 = <0x01>;
			xlnx,has-y-uv8-420 = <0x00>;
			xlnx,has-yuyv8 = <0x00>;
			xlnx,has-y-u-v8 = <0x00>;
			interrupt-names = "interrupt";
			compatible = "xlnx,v-frmbuf-rd-3.0\0xlnx,axi-frmbuf-rd-v2.2";
			xlnx,max-width = <0x780>;
			xlnx,has-rgb16 = <0x00>;
			xlnx,vid-formats = "bgr888";
			xlnx,has-bgrx8 = <0x00>;
			xlnx,has-rgbx8 = <0x00>;
			xlnx,has-rgbx10 = <0x00>;
			interrupt-parent = <0x16>;
			xlnx,aximm-num-outstanding = <0x04>;
			xlnx,has-uyvy8 = <0x00>;
			xlnx,use-uram = <0x00>;
			xlnx,has-rgbx12 = <0x00>;
			xlnx,aximm-burst-length = <0x10>;
			xlnx,aximm-addr-width = <0x20>;
			xlnx,video-width = <0x08>;
			xlnx,max-cols = <0x780>;
			xlnx,has-yuv8 = <0x00>;
			status = "okay";
			xlnx,has-y-uv10-420 = <0x00>;
			xlnx,has-yuva8 = <0x00>;
			xlnx,has-y-uv12-420 = <0x00>;
			xlnx,name = "v_frmbuf_rd_0";
			interrupts = <0x00 0x1e 0x04>;
			xlnx,has-y10 = <0x00>;
			xlnx,has-y-uv16-420 = <0x00>;
			xlnx,has-y12 = <0x00>;
			xlnx,has-alpha = <0x00>;
			xlnx,has-y-u-v10 = <0x00>;
			clocks = <0x24 0x10>;
			xlnx,has-y16 = <0x00>;
			xlnx,dma-align = <0x08>;
			xlnx,has-y-u-v12 = <0x00>;
			xlnx,edk-iptype = "PERIPHERAL";
			xlnx,has-interlaced = <0x00>;
			xlnx,has-yuv16 = <0x00>;
			xlnx,has-yuvx8 = <0x00>;
			xlnx,is-tile-format = <0x00>;
			xlnx,dma-addr-width = <0x20>;
			clock-names = "ap_clk";
			xlnx,s-axi-ctrl-data-width = <0x20>;
			xlnx,has-y8 = <0x00>;
			xlnx,has-y-uv10 = <0x00>;
			xlnx,has-y-uv12 = <0x00>;
			xlnx,max-rows = <0x438>;
			xlnx,has-yuvx10 = <0x00>;
			#dma-cells = <0x01>;
			xlnx,has-yuvx12 = <0x00>;
			xlnx,has-y-uv16 = <0x00>;
			xlnx,max-data-width = <0x08>;
			xlnx,has-y-u-v8-420 = <0x00>;
			xlnx,num-video-components = <0x03>;
			xlnx,aximm-data-width = <0x40>;
			phandle = <0x09>;
		};

		v_frmbuf_wr@43c30000 {
			xlnx,has-y-uv8 = <0x00>;
			xlnx,max-height = <0x438>;
			xlnx,has-bgra8 = <0x00>;
			xlnx,has-rgba8 = <0x00>;
			xlnx,ip-name = "v_frmbuf_wr";
			reg = <0x43c30000 0x10000>;
			xlnx,s-axi-ctrl-addr-width = <0x07>;
			xlnx,pixels-per-clock = <0x01>;
			xlnx,samples-per-clock = <0x01>;
			xlnx,max-nr-planes = <0x01>;
			xlnx,has-bgr8 = <0x00>;
			xlnx,has-rgb8 = <0x01>;
			xlnx,has-y-uv8-420 = <0x00>;
			xlnx,has-yuyv8 = <0x00>;
			xlnx,has-y-u-v8 = <0x00>;
			interrupt-names = "interrupt";
			compatible = "xlnx,v-frmbuf-wr-3.0\0xlnx,axi-frmbuf-wr-v2.2";
			xlnx,max-width = <0x780>;
			xlnx,has-rgb16 = <0x00>;
			xlnx,vid-formats = "bgr888";
			xlnx,has-bgrx8 = <0x00>;
			xlnx,has-rgbx8 = <0x00>;
			xlnx,has-rgbx10 = <0x00>;
			interrupt-parent = <0x16>;
			xlnx,aximm-num-outstanding = <0x04>;
			xlnx,has-uyvy8 = <0x00>;
			xlnx,use-uram = <0x00>;
			xlnx,has-rgbx12 = <0x00>;
			xlnx,aximm-burst-length = <0x10>;
			xlnx,aximm-addr-width = <0x20>;
			xlnx,video-width = <0x08>;
			xlnx,max-cols = <0x780>;
			xlnx,has-yuv8 = <0x00>;
			status = "okay";
			xlnx,has-y-uv10-420 = <0x00>;
			xlnx,has-yuva8 = <0x00>;
			xlnx,has-y-uv12-420 = <0x00>;
			xlnx,name = "v_frmbuf_wr_0";
			interrupts = <0x00 0x1d 0x04>;
			xlnx,has-y10 = <0x00>;
			xlnx,has-y-uv16-420 = <0x00>;
			xlnx,has-y12 = <0x00>;
			xlnx,has-alpha = <0x00>;
			xlnx,has-y-u-v10 = <0x00>;
			clocks = <0x24 0x10>;
			xlnx,has-y16 = <0x00>;
			xlnx,dma-align = <0x08>;
			xlnx,has-y-u-v12 = <0x00>;
			xlnx,edk-iptype = "PERIPHERAL";
			xlnx,has-interlaced = <0x00>;
			xlnx,has-yuv16 = <0x00>;
			xlnx,has-yuvx8 = <0x00>;
			xlnx,is-tile-format = <0x00>;
			xlnx,dma-addr-width = <0x20>;
			clock-names = "ap_clk";
			xlnx,s-axi-ctrl-data-width = <0x20>;
			xlnx,has-y8 = <0x00>;
			xlnx,has-y-uv10 = <0x00>;
			xlnx,has-y-uv12 = <0x00>;
			xlnx,max-rows = <0x438>;
			xlnx,has-yuvx10 = <0x00>;
			#dma-cells = <0x01>;
			xlnx,has-yuvx12 = <0x00>;
			xlnx,has-y-uv16 = <0x00>;
			xlnx,max-data-width = <0x08>;
			xlnx,has-y-u-v8-420 = <0x00>;
			xlnx,num-video-components = <0x03>;
			xlnx,aximm-data-width = <0x40>;
			phandle = <0x08>;
		};

		v_tc_0@43c20000 {
			xlnx,gen-vsync-en = <0x01>;
			xlnx,gen-hframe-size = <0x898>;
			xlnx,num-fsyncs = <0x01>;
			xlnx,gen-hactive-size = <0x780>;
			xlnx,gen-video-format = <0x02>;
			xlnx,gen-f1-vblank-hstart = <0x7d8>;
			xlnx,active-video-detection;
			xlnx,horizontal-sync-generation;
			xlnx,gen-vblank-en = <0x01>;
			xlnx,gen-avideo-en = <0x01>;
			xlnx,ip-name = "v_tc";
			xlnx,fsync-hstart10 = <0x00>;
			xlnx,max-pixels = <0x1000>;
			xlnx,gen-fieldid-en = <0x00>;
			reg = <0x43c20000 0x10000>;
			xlnx,det-vblank-en = <0x01>;
			xlnx,fsync-hstart11 = <0x00>;
			xlnx,fsync-hstart12 = <0x00>;
			xlnx,pixels-per-clock = <0x04>;
			xlnx,gen-interlaced = <0x00>;
			xlnx,det-avideo-en = <0x01>;
			xlnx,fsync-hstart13 = <0x00>;
			xlnx,fsync-hstart14 = <0x00>;
			xlnx,gen-f0-vblank-hend = <0x7d8>;
			xlnx,fsync-hstart15 = <0x00>;
			xlnx,det-hsync-en = <0x01>;
			interrupt-names = "irq";
			xlnx,enable-generation;
			xlnx,gen-avideo-polarity = <0x01>;
			xlnx,max-lines-per-frame = <0x1000>;
			xlnx,has-axi4-lite = <0x01>;
			compatible = "xlnx,v-tc-6.2\0xlnx,bridge-v-tc-6.1";
			xlnx,max-clocks-per-line = <0x1000>;
			xlnx,gen-f0-vframe-size = <0x465>;
			xlnx,gen-f0-vblank-hstart = <0x7d8>;
			interrupt-parent = <0x16>;
			xlnx,max-lines = <0x1000>;
			xlnx,gen-f0-vsync-vstart = <0x43b>;
			xlnx,horizontal-blank-generation;
			xlnx,gen-hsync-end = <0x804>;
			xlnx,gen-f0-vsync-hstart = <0x7d8>;
			xlnx,gen-f1-vsync-hend = <0x7d8>;
			xlnx,vertical-blank-detection;
			xlnx,gen-vsync-polarity = <0x01>;
			xlnx,fsync-vstart0 = <0x00>;
			xlnx,gen-hsync-polarity = <0x01>;
			xlnx,fsync-vstart1 = <0x00>;
			status = "okay";
			xlnx,fsync-vstart2 = <0x00>;
			xlnx,gen-hsync-start = <0x7d8>;
			xlnx,gen-f0-vsync-vend = <0x440>;
			xlnx,fsync-vstart3 = <0x00>;
			xlnx,vertical-sync-detection;
			xlnx,frame-syncs = <0x01>;
			xlnx,fsync-vstart4 = <0x00>;
			xlnx,gen-vactive-size = <0x438>;
			xlnx,name = "v_tc_0";
			xlnx,fsync-vstart5 = <0x00>;
			interrupts = <0x00 0x20 0x04>;
			xlnx,gen-achroma-en = <0x00>;
			xlnx,fsync-vstart6 = <0x00>;
			xlnx,det-fieldid-en = <0x00>;
			xlnx,fsync-vstart7 = <0x00>;
			xlnx,gen-hsync-en = <0x01>;
			xlnx,fsync-vstart8 = <0x00>;
			xlnx,fsync-vstart10 = <0x00>;
			xlnx,fsync-vstart9 = <0x00>;
			xlnx,fsync-vstart11 = <0x00>;
			xlnx,arbitrary-res-en = [00];
			xlnx,fsync-vstart12 = <0x00>;
			xlnx,fsync-vstart13 = <0x00>;
			clocks = <0x32 0x24 0x0f>;
			xlnx,fsync-vstart14 = <0x00>;
			xlnx,fsync-vstart15 = <0x00>;
			xlnx,gen-cparity = <0x00>;
			xlnx,edk-iptype = "PERIPHERAL";
			xlnx,vertical-sync-generation;
			xlnx,gen-f1-vblank-hend = <0x7d8>;
			xlnx,det-vsync-en = <0x01>;
			xlnx,gen-vblank-polarity = <0x01>;
			xlnx,fsync-hstart0 = <0x00>;
			clock-names = "clk\0s_axi_aclk";
			xlnx,interlace-en = <0x00>;
			xlnx,gen-auto-switch = <0x00>;
			xlnx,fsync-hstart1 = <0x00>;
			xlnx,fsync-hstart2 = <0x00>;
			xlnx,active-video-generation;
			xlnx,fsync-hstart3 = <0x00>;
			xlnx,fsync-hstart4 = <0x00>;
			xlnx,horizontal-blank-detection;
			xlnx,fsync-hstart5 = <0x00>;
			xlnx,gen-f1-vframe-size = <0x465>;
			xlnx,fsync-hstart6 = <0x00>;
			xlnx,fsync-hstart7 = <0x00>;
			xlnx,fsync-hstart8 = <0x00>;
			xlnx,gen-hblank-en = <0x01>;
			xlnx,fsync-hstart9 = <0x00>;
			xlnx,horizontal-sync-detection;
			xlnx,gen-f1-vsync-vend = <0x440>;
			xlnx,detect-en = <0x00>;
			xlnx,det-hblank-en = <0x01>;
			xlnx,vid-ppc = <0x04>;
			xlnx,has-intc-if = <0x00>;
			xlnx,generate-en = <0x01>;
			xlnx,gen-achroma-polarity = <0x01>;
			xlnx,sync-en = <0x00>;
			xlnx,det-achroma-en = <0x00>;
			xlnx,generator;
			xlnx,gen-f1-vsync-vstart = <0x43b>;
			xlnx,vertical-blank-generation;
			xlnx,gen-hblank-polarity = <0x01>;
			xlnx,video-mode = "1080p";
			xlnx,gen-fieldid-polarity = <0x01>;
			xlnx,gen-f1-vsync-hstart = <0x7d8>;
			xlnx,gen-f0-vsync-hend = <0x7d8>;
			phandle = <0x07>;
		};

		v_tpg@43c00000 {
			interrupts = <0x00 0x1f 0x04>;
			compatible = "xlnx,v-tpg-8.2\0xlnx,v-tpg-8.0";
			xlnx,max-width = <0x780>;
			xlnx,foreground = <0x01>;
			xlnx,max-height = <0x438>;
			interrupt-parent = <0x16>;
			xlnx,max-rows = <0x438>;
			xlnx,solid-color = <0x01>;
			xlnx,has-axi4-yuv422-yuv420 = <0x00>;
			xlnx,ip-name = "v_tpg";
			reg = <0x43c00000 0x10000>;
			clocks = <0x24 0x10>;
			xlnx,color-bar = <0x01>;
			xlnx,s-axi-ctrl-addr-width = <0x08>;
			xlnx,samples-per-clock = <0x01>;
			xlnx,max-data-width = <0x08>;
			xlnx,has-axi4s-slave = <0x00>;
			xlnx,ppc = <0x01>;
			xlnx,max-cols = <0x780>;
			xlnx,edk-iptype = "PERIPHERAL";
			status = "okay";
			clock-names = "ap_clk";
			xlnx,zone-plate = <0x01>;
			xlnx,num-video-components = <0x03>;
			interrupt-names = "interrupt";
			xlnx,ramp = <0x01>;
			xlnx,color-sweep = <0x01>;
			xlnx,s-axi-ctrl-data-width = <0x20>;
			xlnx,display-port = <0x01>;
			xlnx,name = "v_tpg_0";
			phandle = <0x05>;

			ports {
				#address-cells = <0x01>;
				#size-cells = <0x00>;
				phandle = <0x55>;

				port@1 {
					xlnx,video-width = <0x08>;
					reg = <0x01>;
					xlnx,video-format = <0x02>;
					phandle = <0x56>;

					endpoint {
						remote-endpoint = <0x33>;
						phandle = <0x34>;
					};
				};

				port@0 {
					xlnx,video-width = <0x08>;
					reg = <0x00>;
					xlnx,video-format = <0x02>;
					phandle = <0x57>;
				};
			};
		};

		vcap_v_tpg_0 {
			compatible = "xlnx,video";
			dmas = <0x08 0x00>;
			dma-names = "port0";

			ports {
				#address-cells = <0x01>;
				#size-cells = <0x00>;
				phandle = <0x58>;

				port@0 {
					direction = "input";
					reg = <0x00>;
					phandle = <0x59>;

					endpoint {
						remote-endpoint = <0x34>;
						phandle = <0x33>;
					};
				};
			};
		};
	};

	memory@00100000 {
		compatible = "xlnx,ps7-ddr-1.00.a";
		xlnx,ip-name = "ps7_ddr";
		device_type = "memory";
		memory_type = "memory";
		reg = <0x100000 0x1ff00000>;
		phandle = <0x02>;
	};

	memory@0 {
		compatible = "xlnx,ps7-ram-1.00.a";
		xlnx,ip-name = "ps7_ram";
		device_type = "memory";
		memory_type = "memory";
		reg = <0x00 0x30000>;
		phandle = <0x03>;
	};

	memory@ffff0000 {
		compatible = "xlnx,ps7-ram-1.00.a";
		xlnx,ip-name = "ps7_ram";
		device_type = "memory";
		memory_type = "memory";
		reg = <0xffff0000 0xfe00>;
		phandle = <0x04>;
	};

	chosen {
		stdout-path = "serial0:115200n8";
	};

	aliases {
		serial0 = "/axi/serial@e0001000";
		serial1 = "/axi/coresight@f8800000";
	};

	__symbols__ {
		cpus_a9 = "/cpus-a9@0";
		ps7_cortexa9_0 = "/cpus-a9@0/cpu@0";
		ps7_cortexa9_1 = "/cpus-a9@0/cpu@1";
		fpga_full = "/fpga-region";
		regulator_vccpint = "/fixedregulator";
		replicator_out_port0 = "/replicator/out-ports/port@0/endpoint";
		replicator_out_port1 = "/replicator/out-ports/port@1/endpoint";
		replicator_in_port0 = "/replicator/in-ports/port/endpoint";
		amba = "/axi";
		adc = "/axi/adc@f8007100";
		can0 = "/axi/can@e0008000";
		can1 = "/axi/can@e0009000";
		gpio0 = "/axi/gpio@e000a000";
		i2c0 = "/axi/i2c@e0004000";
		i2c1 = "/axi/i2c@e0005000";
		intc = "/axi/interrupt-controller@f8f01000";
		L2 = "/axi/cache-controller@f8f02000";
		mc = "/axi/memory-controller@f8006000";
		ocm = "/axi/sram@fffc0000";
		uart0 = "/axi/serial@e0000000";
		uart1 = "/axi/serial@e0001000";
		spi0 = "/axi/spi@e0006000";
		spi1 = "/axi/spi@e0007000";
		qspi = "/axi/spi@e000d000";
		gem0 = "/axi/ethernet@e000b000";
		gem1 = "/axi/ethernet@e000c000";
		smcc = "/axi/memory-controller@e000e000";
		nfc0 = "/axi/memory-controller@e000e000/nand-controller@0,0";
		nor0 = "/axi/memory-controller@e000e000/flash@1,0";
		sdhci0 = "/axi/mmc@e0100000";
		sdhci1 = "/axi/mmc@e0101000";
		slcr = "/axi/slcr@f8000000";
		clkc = "/axi/slcr@f8000000/clkc@100";
		rstc = "/axi/slcr@f8000000/rstc@200";
		pinctrl0 = "/axi/slcr@f8000000/pinctrl@700";
		dmac_s = "/axi/dma-controller@f8003000";
		devcfg = "/axi/devcfg@f8007000";
		efuse = "/axi/efuse@f800d000";
		global_timer = "/axi/timer@f8f00200";
		ttc0 = "/axi/timer@f8001000";
		ttc1 = "/axi/timer@f8002000";
		scutimer = "/axi/timer@f8f00600";
		scuwdt = "/axi/scuwatchdog@f8f00620";
		usb0 = "/axi/usb@e0002000";
		usb1 = "/axi/usb@e0003000";
		watchdog0 = "/axi/watchdog@f8005000";
		coresight = "/axi/coresight@f8800000";
		etb_in_port = "/axi/etb@f8801000/in-ports/port/endpoint";
		tpiu_in_port = "/axi/tpiu@f8803000/in-ports/port/endpoint";
		funnel_out_port = "/axi/funnel@f8804000/out-ports/port/endpoint";
		funnel0_in_port0 = "/axi/funnel@f8804000/in-ports/port@0/endpoint";
		funnel0_in_port1 = "/axi/funnel@f8804000/in-ports/port@1/endpoint";
		ptm0_out_port = "/axi/ptm@f889c000/out-ports/port/endpoint";
		ptm1_out_port = "/axi/ptm@f889d000/out-ports/port/endpoint";
		processing_system7_0 = "/axi/processing_system7@0";
		ps7_pmu_0 = "/axi/ps7_pmu@f8891000";
		ps7_ddr_0 = "/axi/ps7_ddr@100000";
		ps7_ocmc_0 = "/axi/ps7_ocmc@f800c000";
		ps7_gpv_0 = "/axi/ps7_gpv@f8900000";
		ps7_scuc_0 = "/axi/ps7_scuc@f8f00000";
		ps7_iop_bus_config_0 = "/axi/ps7_iop_bus_config@e0200000";
		ps7_ram_0 = "/axi/ps7_ram@0";
		ps7_ram_1 = "/axi/ps7_ram@ffff0000";
		ps7_dma_ns = "/axi/ps7_dma@f8004000";
		ps7_afi_0 = "/axi/ps7_afi@f8008000";
		ps7_afi_1 = "/axi/ps7_afi@f8009000";
		ps7_afi_2 = "/axi/ps7_afi@f800a000";
		ps7_afi_3 = "/axi/ps7_afi@f800b000";
		ps7_m_axi_gp0 = "/axi/ps7_m_axi_gp@40000000";
		amba_pl = "/amba_pl";
		clocking1 = "/amba_pl/clocking1";
		clocking0 = "/amba_pl/clocking0";
		afi0 = "/amba_pl/afi0@f8008000";
		misc_clk_0 = "/amba_pl/misc_clk_0";
		axi_dynclk_0 = "/amba_pl/axi_dynclk@43c10000";
		v_frmbuf_rd_0 = "/amba_pl/v_frmbuf_rd@43c40000";
		v_frmbuf_wr_0 = "/amba_pl/v_frmbuf_wr@43c30000";
		v_tc_0 = "/amba_pl/v_tc_0@43c20000";
		v_tpg_0 = "/amba_pl/v_tpg@43c00000";
		tpg_portsv_tpg_0 = "/amba_pl/v_tpg@43c00000/ports";
		tpg_port1v_tpg_0 = "/amba_pl/v_tpg@43c00000/ports/port@1";
		tpg_outv_tpg_0 = "/amba_pl/v_tpg@43c00000/ports/port@1/endpoint";
		tpg_port0v_tpg_0 = "/amba_pl/v_tpg@43c00000/ports/port@0";
		vcap_portsv_tpg_0 = "/amba_pl/vcap_v_tpg_0/ports";
		vcap_portv_tpg_0 = "/amba_pl/vcap_v_tpg_0/ports/port@0";
		v_frmbuf_wr_0v_tpg_0 = "/amba_pl/vcap_v_tpg_0/ports/port@0/endpoint";
		ps7_ddr_0_memory = "/memory@00100000";
		ps7_ram_0_memory = "/memory@0";
		ps7_ram_1_memory = "/memory@ffff0000";
	};
};
